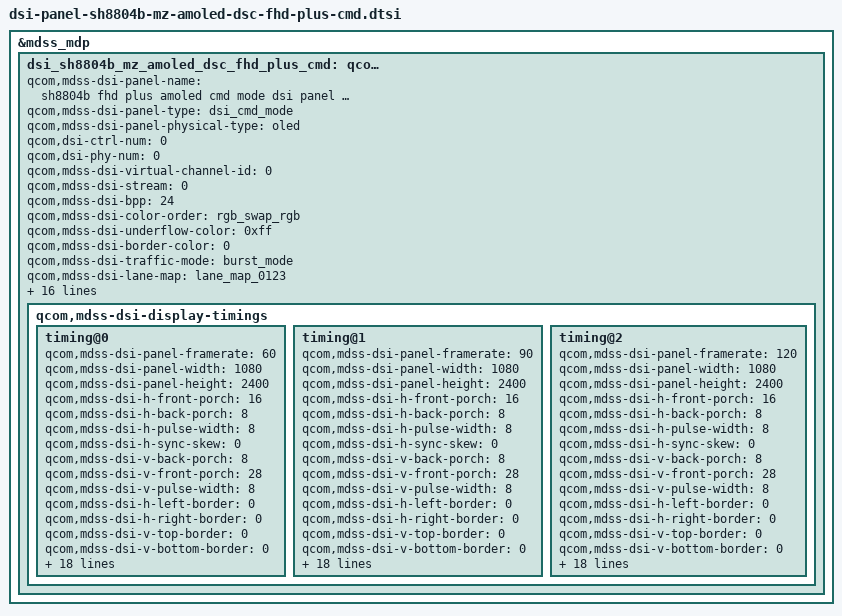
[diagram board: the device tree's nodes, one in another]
&mdss_mdp {
	dsi_sh8804b_mz_amoled_dsc_fhd_plus_cmd: qcom,mdss_dsi_sh8804b_mz_amoled_dsc_fhd_plus_cmd {
		qcom,mdss-dsi-panel-name = "sh8804b fhd plus amoled cmd mode dsi panel with DSC";
		qcom,mdss-dsi-panel-type = "dsi_cmd_mode";
		qcom,mdss-dsi-panel-physical-type = "oled";

		qcom,dsi-ctrl-num = <0>;
		qcom,dsi-phy-num = <0>;

		qcom,mdss-dsi-virtual-channel-id = <0>;
		qcom,mdss-dsi-stream = <0>;
		qcom,mdss-dsi-bpp = <24>;
		qcom,mdss-dsi-color-order = "rgb_swap_rgb";
		qcom,mdss-dsi-underflow-color = <0xff>;
		qcom,mdss-dsi-border-color = <0>;
		qcom,mdss-dsi-traffic-mode = "burst_mode";
		qcom,mdss-dsi-lane-map = "lane_map_0123";
		qcom,mdss-dsi-bllp-eof-power-mode;
		qcom,mdss-dsi-bllp-power-mode;
		qcom,mdss-dsi-lane-0-state;
		qcom,mdss-dsi-lane-1-state;
		qcom,mdss-dsi-lane-2-state;
		qcom,mdss-dsi-lane-3-state;
		qcom,mdss-dsi-dma-trigger = "trigger_sw";
		qcom,mdss-dsi-mdp-trigger = "none";
		qcom,mdss-dsi-reset-sequence = <1 20>, <0 10>, <1 20>;
		qcom,mdss-pan-physical-width-dimension = <69>;
		qcom,mdss-pan-physical-height-dimension = <154>;
		qcom,mdss-dsi-tx-eot-append;

		qcom,mdss-dsi-te-pin-select = <1>;
		qcom,mdss-dsi-te-dcs-command = <1>;
		qcom,mdss-dsi-te-check-enable;
		qcom,mdss-dsi-te-using-te-pin;

		qcom,mdss-dsi-display-timings {
			timing@0 {
				qcom,mdss-dsi-panel-framerate = <60>;
				qcom,mdss-dsi-panel-width = <1080>;
				qcom,mdss-dsi-panel-height = <2400>;
				qcom,mdss-dsi-h-front-porch = <16>;
				qcom,mdss-dsi-h-back-porch = <8>;
				qcom,mdss-dsi-h-pulse-width = <8>;
				qcom,mdss-dsi-h-sync-skew = <0>;
				qcom,mdss-dsi-v-back-porch = <8>;
				qcom,mdss-dsi-v-front-porch = <28>;
				qcom,mdss-dsi-v-pulse-width = <8>;
				qcom,mdss-dsi-h-left-border = <0>;
				qcom,mdss-dsi-h-right-border = <0>;
				qcom,mdss-dsi-v-top-border = <0>;
				qcom,mdss-dsi-v-bottom-border = <0>;
				//qcom,mdss-dsi-panel-jitter = <0x4 0x1>;
				qcom,mdss-dsi-timing-switch-command = [39 01 00 00 05 00 02 70 00];
				qcom,mdss-dsi-timing-switch-command-state = "dsi_lp_mode";
				qcom,mdss-dsi-on-command = [
					39 01 00 00 00 00 03 F0 3C 3C
					39 01 00 00 00 00 03 F1 3C 3C
					39 01 00 00 00 00 03 FF 3C 00
					39 01 00 00 00 00 05 D0 00 00 00 00
					39 01 00 00 00 00 04 B4 00 00 00
					39 01 00 00 00 00 09 B5 00 40 0A 00 00 C0 0A 00
					39 01 00 00 00 00 03 B7 21 76
					39 01 00 00 00 00 10 C1 02 0C 10 10 44 20 00 00 00 00 00 08 00 00 85
					39 01 00 00 00 00 03 FF 3C 01
					39 01 00 00 00 00 06 B0 50 10 10 15 00
					39 01 00 00 00 00 3B B1 C4 60 09 38 04 D0 02 00 00 00 01 03 00 10 09 60 00 12 00 12 00 10 03 0C 00 12 00 12 00 10 00 10 00 10 00 10 00 10 09 60 00 12 00 12 00 10 00 00 37 04 00 00 5F 09 00 00 FF 00
					39 01 00 00 00 00 17 B2 14 14 03 04 03 04 03 04 07 13 14 14 03 04 03 04 03 04 13 14 14 03
					39 01 00 00 00 00 1B B3 40 01 38 A5 C9 00 30 01 C0 A6 41 00 01 00 00 00 00 11 20 44 35 77 86 AA 9B FF
					39 01 00 00 00 00 06 B4 32 22 26 56 12
					39 01 00 00 00 00 13 B5 00 00 00 00 00 00 04 F0 20 00 00 00 00 00 00 00 00 00
					39 01 00 00 00 00 31 B7 00 FB FC 00 00 00 00 00 00 00 00 00 00 00 00 00 00 00 00 00 00 00 00 00 00 00 00 00 00 00 00 00 00 00 00 00 00 00 00 00 00 00 00 00 00 00 00 00
					39 01 00 00 00 00 0A B8 09 AA 55 AA 55 AA 55 AA 55
					39 01 00 00 00 00 29 BA 24 00 27 00 26 00 0C 00 0B 00 01 00 37 37 37 37 24 00 27 00 26 00 0C 00 0B 00 01 00 37 37 37 37 00 00 00 00 00 00 00 00
					39 01 00 00 00 00 19 BB 00 02 00 00 00 2B 00 00 00 00 79 79 00 00 79 79 00 00 79 79 00 00 79 79
					39 01 00 00 00 00 1B BC 83 01 00 07 00 09 00 0A 00 0C 00 0D 00 0F 00 E6 00 00 E6 00 00 E6 00 00 E6 00
					39 01 00 00 00 00 13 BE 03 00 00 0E 04 00 12 12 00 12 12 00 12 12 00 12 12 00
					39 01 00 00 00 00 12 C0 11 01 00 10 10 64 14 10 64 14 10 64 14 10 64 14 FF
					39 01 00 00 00 00 12 C5 21 02 00 31 00 12 AA 00 12 AA 00 12 AA 00 12 AA FF
					39 01 00 00 00 00 11 C7 66 00 66 00 66 00 00 00 00 66 00 11 00 00 00 00
					39 01 00 00 00 00 32 C8 00 00 00 00 00 00 00 00 06 06 06 00 60 10 00 00 00 00 06 20 00 00 00 00 00 00 00 00 00 00 00 00 00 00 00 00 00 00 00 00 00 00 00 00 00 00 00 00 FF
					39 01 00 00 00 00 63 C9 00 00 25 21 36 00 00 00 56 11 00 00 00 00 00 00 00 00 00 00 00 00 00 00 25 31 26 00 00 00 56 11 00 00 00 00 00 00 00 00 00 00 00 00 00 00 35 12 36 56 12 00 00 00 00 00 00 00 00 00 00 00 00 00 00 00 00 00 00 00 00 35 22 26 00 00 00 56 12 00 00 00 00 00 00 00 00 00 00 00 00 00 00 35 21 26 56 11
					39 01 00 00 00 00 17 CE 01 30 03 03 03 03 03 03 03 03 00 00 02 02 02 00 00 00 00 00 00 FF
					39 01 00 00 00 00 03 FF 3C 02
					39 01 00 00 00 00 1F B0 19 88 08 70 00 54 1E 1E 19 1E 41 10 1E 00 38 77 6C 6C 33 33 33 33 73 33 33 33 32 04 F0 33
					39 01 00 00 00 00 1F B1 09 88 08 6E 00 54 1E 1E 19 1E 41 10 1E 00 38 77 6C 6C 33 33 33 33 73 33 33 33 32 04 F0 33
					39 01 00 00 00 00 2C B2 00 00 77 19 21 29 01 03 05 07 07 08 09 0A 0D 0F 21 25 25 1C 00 77 19 21 29 01 03 05 07 08 09 0A 0B 0D 0F 25 21 21 00 00 00 00 FF
					39 01 00 00 00 00 29 B3 00 00 00 00 01 01 02 03 03 07 04 04 05 06 07 07 08 08 09 09 09 09 09 8B 8C 09 0A 09 0B 0C 0C 0C 00 0E 18 1C 00 00 21 00
					39 01 00 00 00 00 29 B3 00 00 00 00 01 01 02 03 03 07 04 04 05 06 07 07 08 08 09 09 09 09 09 8B 8C 09 0A 09 0B 0C 0C 0C 00 0E 14 18 00 00 21 00
					39 01 00 00 00 00 17 B4 BB BB B0 AA 9A 88 88 78 77 77 77 77 77 77 77 88 08 EC 44 00 21 00
					39 01 00 00 00 00 17 B5 22 22 20 11 11 11 11 00 00 00 00 00 00 00 00 00 00 02 00 00 00 FF
					39 01 00 00 00 00 20 BA 0F 0F 0F 0F 0F 0F 0F 0F 0F 0F 0F 0F 14 15 16 17 18 19 19 19 19 19 19 19 0F 0F 0F 19 19 19 00
					39 01 00 00 00 00 03 FF 3C 03
					39 01 00 00 00 00 A7 B0 00 00 FF 05 00 00 00 00 00 00 98 03 E8 03 1D 04 9A 03 E8 03 1F 04 9F 03 E9 03 24 04 A4 03 EA 03 29 04 A9 03 EB 03 2E 04 AE 03 EC 03 33 04 B3 03 ED 03 38 04 B8 03 EE 03 3D 04 BD 03 EF 03 42 04 C2 03 F0 03 47 04 C7 03 F1 03 4C 04 D2 03 F4 03 56 04 DD 03 F7 03 60 04 E8 03 FA 03 6A 04 FF 03 00 04 7F 04 16 04 06 04 94 04 2D 04 0C 04 A9 04 44 04 12 04 BE 04 44 04 12 04 BE 04 56 04 18 04 CB 04 5F 04 18 04 D2 04 5F 04 18 04 D2 04 91 04 3E 04 08 05 91 04 3E 04 08 05 91 04 3E 04 08 05 91 04 3E 04 08 05
					39 01 00 00 00 00 A7 B1 00 00 FF 05 00 00 00 00 00 00 44 03 36 03 B4 03 0C 04 FE 03 7C 04 70 04 62 04 E0 04 95 04 80 04 18 05 AB 04 94 04 3A 05 C7 04 9F 04 52 05 06 05 D0 04 90 05 10 05 D0 04 98 05 21 05 DB 04 AC 05 37 05 EB 04 C7 05 4B 05 FA 04 DB 05 69 05 0E 05 FB 05 8E 05 2A 05 21 06 AB 05 43 05 42 06 DD 05 6D 05 79 06 11 06 9B 05 B2 06 41 06 C7 05 E6 06 6B 06 EB 05 16 07 98 06 15 06 47 07 BC 06 37 06 71 07 E0 06 58 06 99 07 0C 07 82 06 CE 07 25 07 9B 06 E7 07 3F 07 B2 06 04 08 5C 07 CC 06 27 08 7C 07 EC 06 49 08
					39 01 00 00 00 00 A7 B2 00 00 FF 05 00 00 00 00 00 00 9B 03 84 01 00 00 78 04 67 04 0B 05 78 04 67 04 0B 05 B5 04 88 04 3A 05 D4 04 A2 04 5B 05 F1 04 B6 04 7D 05 39 05 EF 04 C3 05 44 05 F4 04 D2 05 5F 05 07 05 F0 05 7A 05 1C 05 0C 06 92 05 30 05 26 06 B4 05 4A 05 4B 06 DE 05 6E 05 78 06 04 06 8F 05 A2 06 3F 06 C5 05 E4 06 79 06 F9 05 26 07 AF 06 2A 06 63 07 E3 06 5C 06 9D 07 10 07 86 06 D1 07 39 07 AC 06 02 08 60 07 D2 06 2E 08 84 07 F3 06 58 08 AA 07 17 07 83 08 CC 07 36 07 AA 08 EB 07 53 07 CE 08 11 08 70 07 F4 08
					39 01 00 00 00 00 A7 B3 00 00 FF 05 00 00 00 00 00 00 89 03 C5 03 7A 01 EF 03 5F 04 55 02 83 04 6E 04 14 05 D2 04 93 04 54 05 F1 04 B1 04 7F 05 1B 05 D0 04 AB 05 67 05 11 05 F6 05 79 05 1D 05 0B 06 98 05 33 05 2C 06 B2 05 4C 05 48 06 CE 05 62 05 67 06 F7 05 85 05 95 06 24 06 AE 05 C6 06 4D 06 D3 05 F4 06 90 06 0F 06 41 07 D2 06 4C 06 8A 07 0E 07 85 06 CD 07 42 07 B6 06 0B 08 76 07 E5 06 47 08 A4 07 13 07 7C 08 CE 07 38 07 AD 08 F6 07 5E 07 DB 08 20 08 85 07 0C 09 46 08 A8 07 37 09 6A 08 CA 07 62 09 90 08 EA 07 90 09
					39 01 00 00 00 00 A7 B4 00 00 FF 05 00 00 00 00 00 00 E6 03 F1 03 8B 04 4A 04 55 04 EF 04 9C 04 71 04 21 05 E1 04 A6 04 6C 05 17 05 C9 04 A5 05 46 05 ED 04 D6 05 97 05 38 05 2A 06 AC 05 44 05 41 06 D2 05 65 05 6A 06 EE 05 7F 05 89 06 0C 06 99 05 AA 06 3A 06 C2 05 DF 06 6B 06 EF 05 16 07 99 06 19 06 4A 07 E4 06 5E 06 9E 07 29 07 9F 06 EE 07 68 07 DB 06 37 08 9F 07 0D 07 78 08 DD 07 49 07 BD 08 0C 08 73 07 F5 08 3B 08 9E 07 2D 09 6A 08 C7 07 64 09 99 08 F4 07 9B 09 C3 08 1A 08 CD 09 ED 08 3F 08 FF 09 19 09 65 08 32 0A
					39 01 00 00 00 00 A7 B5 00 00 FF 05 00 00 00 00 00 00 F6 03 ED 03 8C 04 5A 04 51 04 F0 04 9E 04 73 04 2B 05 F2 04 B2 04 82 05 2E 05 DA 04 BE 05 61 05 02 05 F2 05 B3 05 4D 05 48 06 C9 05 5E 05 61 06 ED 05 7F 05 88 06 0F 06 9C 05 AE 06 2F 06 B9 05 D0 06 60 06 E6 05 0A 07 95 06 16 06 44 07 C4 06 41 06 7B 07 0E 07 85 06 D2 07 5D 07 D0 06 28 08 9D 07 0D 07 74 08 D8 07 43 07 BA 08 15 08 7C 07 00 09 4B 08 AD 07 40 09 7F 08 DB 07 7D 09 AF 08 09 08 B6 09 E2 08 36 08 F1 09 11 09 5F 08 29 0A 3F 09 87 08 5F 0A 70 09 B2 08 99 0A
					39 01 00 00 00 00 A7 B6 00 00 FF 05 00 00 00 00 00 00 01 00 B8 03 F2 04 5E 04 50 04 F2 04 A6 04 77 04 31 05 FF 04 B8 04 8C 05 3C 05 E3 04 CD 05 71 05 0D 05 03 06 C4 05 5D 05 5B 06 DC 05 71 05 75 06 FF 05 8F 05 9C 06 23 06 AF 05 C3 06 43 06 CC 05 E7 06 76 06 FA 05 22 07 AC 06 2B 06 5F 07 E4 06 5F 06 9D 07 2B 07 A1 06 F1 07 77 07 E8 06 49 08 BA 07 27 07 96 08 F8 07 61 07 DF 08 38 08 9C 07 28 09 70 08 CE 07 6B 09 A5 08 FE 07 A9 09 D8 08 2C 08 E6 09 0E 09 5D 08 25 0A 3F 09 88 08 5F 0A 6F 09 B2 08 98 0A A2 09 DD 08 D4 0A
					39 01 00 00 00 00 A7 B7 00 00 FF 05 00 00 00 00 00 00 33 00 C1 03 EE 04 62 04 54 04 F6 04 B3 04 7E 04 3E 05 10 05 C2 04 9E 05 4F 05 F2 04 E1 05 85 05 1F 05 19 06 DA 05 70 05 73 06 F3 05 84 05 8F 06 1C 06 AA 05 BB 06 40 06 C9 05 E2 06 5F 06 E5 05 06 07 93 06 14 06 43 07 CB 06 48 06 82 07 05 07 7C 06 C2 07 4C 07 BF 06 18 08 A1 07 12 07 77 08 E1 07 4B 07 C3 08 24 08 8A 07 11 09 64 08 C4 07 5D 09 9E 08 F9 07 A1 09 D7 08 2B 08 E5 09 0D 09 5C 08 26 0A 46 09 8E 08 67 0A 7B 09 BC 08 A5 0A AE 09 E7 08 E3 0A E6 09 16 09 23 0B
					39 01 00 00 00 00 A7 B8 00 00 FF 05 00 00 00 00 00 00 44 04 43 04 9C 04 69 04 57 04 FB 04 C0 04 87 04 4B 05 22 05 CF 04 B2 05 63 05 03 05 F4 05 9D 05 33 05 33 06 F3 05 87 05 8E 06 11 06 A0 05 AF 06 38 06 C4 05 DB 06 5E 06 E5 05 04 07 7E 06 01 06 2A 07 B5 06 34 06 69 07 F1 06 6C 06 AB 07 1F 07 97 06 E3 07 76 07 E7 06 48 08 C6 07 32 07 A4 08 11 08 78 07 F9 08 54 08 B4 07 49 09 98 08 F4 07 9A 09 D6 08 2B 08 E3 09 12 09 5F 08 2A 0A 4C 09 93 08 6D 0A 8A 09 C8 08 B5 0A C2 09 F8 08 F9 0A FA 09 27 09 3B 0B 37 0A 5B 09 80 0B
					39 01 00 00 00 00 A7 B9 00 00 FF 05 00 00 00 00 00 00 42 04 38 04 01 05 80 04 57 04 01 05 D8 04 8F 04 5C 05 3B 05 E0 04 CA 05 7E 05 18 05 11 06 BB 05 4E 05 53 06 12 06 A3 05 AF 06 32 06 BC 05 D2 06 5B 06 E1 05 00 07 7F 06 04 06 2B 07 A2 06 24 06 53 07 E0 06 5D 06 98 07 1A 07 91 06 DB 07 4B 07 C1 06 16 08 A7 07 15 07 80 08 FA 07 63 07 E0 08 48 08 AB 07 3B 09 90 08 EC 07 91 09 DA 08 2F 08 E7 09 1C 09 6A 08 35 0A 5E 09 A1 08 83 0A 9D 09 D9 08 CD 0A E1 09 13 09 1C 0B 1F 0A 47 09 66 0B 5E 0A 7D 09 AC 0B A1 0A B5 09 FA 0B
					39 01 00 00 00 00 A7 BA 00 00 FF 05 00 00 00 00 00 00 41 04 2E 04 0E 05 7B 04 64 04 0E 05 FA 04 A7 04 7E 05 62 05 01 05 F4 05 AD 05 42 05 44 06 EE 05 7B 05 8C 06 4A 06 D5 05 EE 06 6C 06 F2 05 15 07 98 06 1A 06 46 07 C1 06 3F 06 74 07 E6 06 63 06 9E 07 26 07 9E 06 E8 07 65 07 DA 06 31 08 9D 07 0D 07 73 08 FE 07 65 07 E5 08 59 08 BA 07 4F 09 B0 08 08 08 B4 09 00 09 4F 08 14 0A 54 09 9B 08 76 0A A1 09 DB 08 D4 0A EE 09 1D 09 2D 0B 3A 0A 5D 09 85 0B 88 0A A0 09 DC 0B D6 0A E0 09 3E 0C 23 0B 20 0A 92 0C 74 0B 66 0A F5 0C
					39 01 00 00 00 00 A7 BB 00 00 FF 05 00 00 00 00 00 00 50 04 45 04 DD 04 86 04 68 04 17 05 1C 05 B7 04 B0 05 80 05 1B 05 14 06 D1 05 62 05 6C 06 13 06 9E 05 B3 06 72 06 FA 05 19 07 95 06 18 06 43 07 C3 06 43 06 76 07 EF 06 6A 06 A8 07 17 07 91 06 D4 07 58 07 CC 06 23 08 99 07 0A 07 6D 08 D7 07 43 07 B4 08 3D 08 A0 07 2D 09 A1 08 FB 07 A3 09 FB 08 4B 08 0D 0A 57 09 9C 08 79 0A B2 09 E9 08 E6 0A 08 0A 33 09 4B 0B 5F 0A 7B 09 AE 0B B5 0A C4 09 12 0C 10 0B 11 0A 7D 0C 69 0B 5B 0A E6 0C C4 0B A8 0A 54 0D 2B 0C FE 0A D7 0D
					39 01 00 00 00 00 A7 C0 00 00 FF 05 00 00 00 00 00 00 F2 03 03 04 8D 04 F3 03 03 04 8D 04 F5 03 04 04 8E 04 F7 03 05 04 8F 04 F9 03 06 04 90 04 FB 03 07 04 91 04 FD 03 08 04 92 04 FF 03 09 04 93 04 01 04 0A 04 94 04 03 04 0B 04 95 04 05 04 0C 04 96 04 0A 04 0E 04 99 04 0F 04 10 04 9C 04 14 04 12 04 9F 04 1E 04 16 04 A6 04 28 04 1A 04 AD 04 32 04 1E 04 B4 04 3C 04 22 04 BB 04 46 04 26 04 C2 04 50 04 2A 04 C9 04 5A 04 2A 04 D2 04 69 04 2C 04 DF 04 69 04 2C 04 DF 04 87 04 3C 04 FB 04 87 04 3C 04 FB 04 87 04 3C 04 FB 04
					39 01 00 00 00 00 A7 C1 00 00 FF 05 00 00 00 00 00 00 42 03 01 00 25 01 42 03 01 00 25 01 42 03 01 00 5C 05 CF 04 BE 04 5C 05 CF 04 BE 04 5C 05 E4 04 C9 04 72 05 10 05 F2 04 9D 05 20 05 F2 04 AC 05 33 05 FC 04 BF 05 45 05 07 05 D5 05 56 05 12 05 E7 05 72 05 21 05 03 06 92 05 3A 05 26 06 B3 05 53 05 4A 06 E3 05 78 05 7E 06 13 06 A2 05 B3 06 41 06 CA 05 E6 06 6B 06 EF 05 16 07 97 06 18 06 46 07 BC 06 39 06 70 07 DF 06 59 06 97 07 0A 07 82 06 CC 07 23 07 9B 06 E5 07 3E 07 B4 06 05 08 5C 07 CD 06 23 08 79 07 EA 06 47 08
					39 01 00 00 00 00 A7 C2 00 00 FF 05 00 00 00 00 00 00 45 04 35 04 C4 04 A2 04 93 04 2F 05 A2 04 93 04 2F 05 D3 04 B2 04 64 05 E9 04 C7 04 75 05 05 05 D6 04 94 05 4A 05 0D 05 D7 05 52 05 0E 05 DF 05 69 05 1D 05 FC 05 82 05 30 05 14 06 99 05 40 05 2E 06 BA 05 58 05 52 06 E4 05 7A 05 7F 06 06 06 98 05 A5 06 3F 06 C9 05 E5 06 79 06 FC 05 27 07 AE 06 2B 06 62 07 E3 06 5D 06 9C 07 0F 07 87 06 D1 07 39 07 AD 06 01 08 60 07 D3 06 2D 08 89 07 F9 06 5B 08 A9 07 18 07 83 08 CA 07 35 07 A8 08 E9 07 52 07 CD 08 10 08 77 07 F6 08
					39 01 00 00 00 00 A7 C3 00 00 FF 05 00 00 00 00 00 00 00 00 2E 04 D7 04 00 00 99 04 D7 04 AA 04 99 04 39 05 DF 04 BC 04 6C 05 06 05 D3 04 94 05 29 05 E8 04 B9 05 73 05 28 05 03 06 80 05 2E 05 12 06 9E 05 42 05 33 06 B9 05 58 05 51 06 D5 05 6F 05 6E 06 FA 05 8E 05 97 06 26 06 B4 05 C8 06 4F 06 D8 05 F6 06 90 06 10 06 40 07 D1 06 4D 06 8B 07 0D 07 84 06 CB 07 3F 07 B3 06 08 08 78 07 E9 06 47 08 A6 07 14 07 7C 08 CC 07 37 07 AA 08 F4 07 5B 07 D9 08 1E 08 82 07 09 09 43 08 A5 07 35 09 67 08 C5 07 60 09 8F 08 EB 07 8F 09
					39 01 00 00 00 00 A7 C5 00 00 FF 05 00 00 00 00 00 00 9A 04 00 00 0E 05 B8 04 00 00 43 05 B8 04 99 04 43 05 FF 04 C7 04 86 05 25 05 E5 04 B5 05 52 05 04 05 E4 05 9E 05 49 05 32 06 B1 05 53 05 47 06 D1 05 6D 05 6A 06 F0 05 87 05 8C 06 0E 06 A0 05 AC 06 3B 06 C6 05 DF 06 6C 06 F4 05 15 07 99 06 1B 06 49 07 E0 06 5C 06 9A 07 26 07 9E 06 EB 07 66 07 D9 06 33 08 9D 07 0C 07 75 08 DB 07 48 07 BA 08 0A 08 71 07 F2 08 39 08 9C 07 29 09 67 08 C5 07 5F 09 96 08 F1 07 96 09 C1 08 18 08 C9 09 EA 08 3D 08 FA 09 16 09 64 08 30 0A
					39 01 00 00 00 00 A7 C6 00 00 FF 05 00 00 00 00 00 00 A4 04 12 00 0B 05 BD 04 2B 00 24 05 C8 04 99 04 4B 05 05 05 CE 04 94 05 38 05 F0 04 C9 05 67 05 13 05 F9 05 B7 05 5B 05 4E 06 D3 05 6E 05 6C 06 F0 05 87 05 8C 06 14 06 A8 05 B3 06 30 06 BE 05 D2 06 60 06 E9 05 09 07 94 06 18 06 43 07 C4 06 43 06 7A 07 11 07 8A 06 D1 07 5B 07 D0 06 26 08 9B 07 0C 07 71 08 D6 07 43 07 B7 08 16 08 7F 07 FF 08 4C 08 AF 07 3C 09 7C 08 DA 07 78 09 AD 08 05 08 B3 09 E0 08 35 08 EE 09 0F 09 5E 08 25 0A 3B 09 85 08 57 0A 6E 09 AF 08 95 0A
					39 01 00 00 00 00 A7 C7 00 00 FF 05 00 00 00 00 00 00 34 04 15 04 CC 04 98 04 79 04 30 05 C2 04 9E 04 4F 05 0F 05 D6 04 9F 05 48 05 FC 04 DA 05 77 05 1F 05 0A 06 C9 05 69 05 5F 06 E0 05 7A 05 7A 06 04 06 99 05 A2 06 27 06 B7 05 C8 06 47 06 D4 05 EB 06 78 06 FE 05 23 07 AC 06 2D 06 5F 07 E4 06 60 06 9D 07 2C 07 A2 06 F2 07 76 07 E8 06 47 08 B8 07 26 07 94 08 F6 07 61 07 DD 08 37 08 9B 07 27 09 6D 08 CD 07 68 09 A2 08 FC 07 A6 09 D6 08 2B 08 E2 09 0B 09 5A 08 21 0A 3D 09 86 08 5C 0A 6D 09 B0 08 94 0A A0 09 DB 08 D4 0A
					39 01 00 00 00 00 A7 C8 00 00 FF 05 00 00 00 00 00 00 46 04 5A 04 1F 05 9E 04 7A 04 34 05 CC 04 A3 04 57 05 1C 05 DE 04 AD 05 57 05 07 05 E7 05 8A 05 2E 05 1F 06 DF 05 7C 05 77 06 F5 05 8C 05 91 06 1A 06 AC 05 BA 06 3D 06 CB 05 E1 06 5F 06 E8 05 06 07 96 06 1A 06 45 07 C8 06 47 06 7F 07 01 07 7A 06 BF 07 49 07 BD 06 15 08 9A 07 0B 07 71 08 E0 07 4B 07 C1 08 20 08 86 07 0D 09 62 08 C3 07 5B 09 9C 08 F8 07 9F 09 D2 08 27 08 DE 09 0A 09 59 08 22 0A 44 09 8C 08 64 0A 78 09 B9 08 A1 0A AC 09 E6 08 DE 0A E2 09 13 09 1F 0B
					39 01 00 00 00 00 A7 C9 00 00 FF 05 00 00 00 00 00 00 94 04 24 04 C1 04 94 04 86 04 24 05 D6 04 AA 04 63 05 2D 05 E8 04 BE 05 6C 05 16 05 FE 05 A1 05 3F 05 38 06 F6 05 8F 05 90 06 10 06 A4 05 AF 06 37 06 C7 05 DA 06 5E 06 E8 05 04 07 7E 06 04 06 29 07 B4 06 35 06 67 07 ED 06 69 06 A8 07 1E 07 98 06 E1 07 74 07 E6 06 45 08 C4 07 31 07 A2 08 0D 08 75 07 F6 08 51 08 B2 07 46 09 95 08 F1 07 96 09 D3 08 29 08 E0 09 0F 09 5C 08 27 0A 49 09 90 08 6A 0A 86 09 C5 08 B1 0A BF 09 F7 08 F5 0A F7 09 24 09 37 0B 30 0A 57 09 7A 0B
					39 01 00 00 00 00 A7 CA 00 00 FF 05 00 00 00 00 00 00 4A 04 3B 04 2A 05 97 04 89 04 2A 05 E4 04 B2 04 72 05 43 05 F8 04 D5 05 85 05 29 05 1A 06 BC 05 56 05 56 06 13 06 AA 05 B0 06 33 06 C1 05 D5 06 59 06 E3 05 FF 06 80 06 07 06 2C 07 A2 06 26 06 52 07 DD 06 5C 06 95 07 17 07 90 06 D8 07 4C 07 C3 06 16 08 A5 07 16 07 7C 08 F7 07 61 07 DD 08 45 08 A8 07 37 09 8D 08 E9 07 8D 09 D7 08 2C 08 E4 09 19 09 66 08 31 0A 5A 09 9F 08 7E 0A 9A 09 D6 08 C9 0A DE 09 10 09 18 0B 1C 0A 44 09 63 0B 5A 0A 79 09 AB 0B 9D 0A B2 09 F8 0B
					39 01 00 00 00 00 A7 CB 00 00 FF 05 00 00 00 00 00 00 7B 04 6F 04 24 05 A2 04 8F 04 32 05 07 05 C3 04 8F 05 6A 05 14 05 FB 05 B4 05 50 05 4D 06 F0 05 83 05 8E 06 4D 06 DB 05 EF 06 6D 06 F6 05 14 07 98 06 1D 06 45 07 C1 06 42 06 75 07 E7 06 64 06 9F 07 24 07 9D 06 E7 07 63 07 D8 06 2F 08 9B 07 0B 07 71 08 FC 07 63 07 E2 08 57 08 B8 07 4D 09 AD 08 06 08 B2 09 FC 08 4C 08 11 0A 51 09 97 08 73 0A 9F 09 DA 08 CE 0A EB 09 1A 09 2A 0B 37 0A 5A 09 82 0B 86 0A 9E 09 DE 0B D3 0A DD 09 37 0C 20 0B 1D 0A 8F 0C 71 0B 61 0A F8 0C
					39 01 00 00 00 00 A7 CC 00 00 FF 05 00 00 00 00 00 00 B2 04 6F 02 1E 00 B3 04 93 04 22 05 0E 05 D2 04 A5 05 87 05 2A 05 1B 06 D4 05 6C 05 6F 06 14 06 A3 05 B7 06 73 06 FD 05 1A 07 96 06 1C 06 43 07 C3 06 44 06 77 07 EE 06 6D 06 A7 07 17 07 92 06 D5 07 57 07 CD 06 23 08 98 07 0A 07 6D 08 D5 07 41 07 B4 08 3A 08 9D 07 2A 09 9D 08 F8 07 A0 09 F8 08 49 08 0A 0A 53 09 97 08 75 0A AF 09 E8 08 E1 0A 05 0A 30 09 48 0B 5A 0A 78 09 AB 0B B1 0A C0 09 0D 0C 0C 0B 0D 0A 78 0C 65 0B 57 0A E3 0C BF 0B A4 0A 52 0D 29 0C FC 0A D2 0D
					39 01 00 00 00 00 A7 D0 00 00 FF 05 00 00 00 00 00 00 35 04 57 04 9E 04 35 04 57 04 9F 04 36 04 57 04 A1 04 37 04 57 04 A3 04 38 04 57 04 A5 04 39 04 57 04 A7 04 3A 04 57 04 A9 04 3B 04 57 04 AB 04 3C 04 57 04 AD 04 3D 04 57 04 AF 04 3E 04 57 04 B1 04 41 04 57 04 B5 04 44 04 57 04 B9 04 47 04 57 04 BD 04 4E 04 57 04 C5 04 55 04 57 04 CD 04 5C 04 57 04 D5 04 63 04 57 04 DD 04 6A 04 57 04 E5 04 71 04 57 04 ED 04 79 04 57 04 EF 04 85 04 58 04 FB 04 85 04 58 04 FB 04 8F 04 58 04 06 05 91 04 58 04 07 05 9A 04 59 04 0A 05
					39 01 00 00 00 00 A7 D1 00 00 FF 05 00 00 00 00 00 00 A8 04 B0 04 34 05 AF 04 B4 04 3B 05 BE 04 BC 04 4A 05 CD 04 C4 04 59 05 DC 04 CC 04 68 05 EB 04 D4 04 77 05 FC 04 DD 04 89 05 0A 05 E4 04 97 05 1A 05 EC 04 A9 05 2F 05 F8 04 BE 05 3D 05 00 05 CD 05 60 05 17 05 F2 05 7F 05 2E 05 13 06 9D 05 44 05 33 06 D7 05 70 05 73 06 06 06 99 05 A7 06 33 06 BF 05 D9 06 5C 06 E2 05 08 07 84 06 06 06 34 07 A8 06 27 06 5D 07 CB 06 46 06 85 07 EC 06 65 06 AB 07 0A 07 7F 06 CC 07 27 07 9B 06 EE 07 42 07 B5 06 0D 08 58 07 CE 06 2F 08
					39 01 00 00 00 00 A7 D2 00 00 FF 05 00 00 00 00 00 00 9A 04 98 04 2C 05 A7 04 A2 04 38 05 C2 04 B6 04 50 05 DD 04 CA 04 68 05 F1 04 D5 04 7E 05 07 05 DF 04 96 05 21 05 F0 04 B1 05 37 05 FA 04 C6 05 4F 05 09 05 E2 05 64 05 18 05 F7 05 7C 05 29 05 10 06 A6 05 4A 05 3D 06 CC 05 69 05 68 06 F0 05 85 05 8F 06 32 06 BD 05 D8 06 6E 06 F3 05 1B 07 9F 06 1F 06 54 07 D0 06 4C 06 8B 07 FC 06 74 06 BE 07 25 07 9B 06 ED 07 4C 07 BF 06 19 08 6F 07 E0 06 43 08 91 07 FE 06 6A 08 B3 07 1F 07 92 08 D1 07 39 07 B5 08 F1 07 57 07 DB 08
					39 01 00 00 00 00 A7 D3 00 00 FF 05 00 00 00 00 00 00 62 04 6E 04 C3 04 B3 04 A8 04 2D 05 CA 04 BA 04 58 05 ED 04 CA 04 7E 05 05 05 DE 04 98 05 27 05 EE 04 B7 05 47 05 06 05 D8 05 60 05 14 05 F4 05 7E 05 2A 05 15 06 99 05 3F 05 30 06 B2 05 52 05 4A 06 E3 05 7B 05 81 06 0F 06 A0 05 B1 06 38 06 C3 05 E0 06 81 06 04 06 32 07 C3 06 42 06 7B 07 FC 06 74 06 BD 07 31 07 A6 06 F9 07 61 07 D2 06 32 08 91 07 01 07 6A 08 B7 07 22 07 95 08 E0 07 48 07 C4 08 06 08 6B 07 F2 08 2B 08 8D 07 1D 09 4F 08 AE 07 48 09 75 08 D1 07 72 09
					39 01 00 00 00 00 A7 D4 00 00 FF 05 00 00 00 00 00 00 76 04 4F 04 E6 04 76 04 A9 04 42 05 D1 04 BD 04 5E 05 FA 04 D5 04 88 05 22 05 EB 04 B3 05 49 05 05 05 DA 05 71 05 20 05 04 06 90 05 37 05 26 06 B3 05 51 05 4D 06 D2 05 6C 05 6F 06 EE 05 82 05 8B 06 24 06 B2 05 C8 06 54 06 DD 05 FE 06 82 06 04 06 32 07 D2 06 50 06 8D 07 18 07 8F 06 DC 07 56 07 CA 06 25 08 8F 07 FF 06 67 08 C4 07 2F 07 A4 08 F8 07 62 07 E1 08 25 08 88 07 15 09 52 08 B1 07 4A 09 80 08 DA 07 7F 09 AA 08 00 08 B1 09 D3 08 25 08 E3 09 FE 08 49 08 17 0A
					39 01 00 00 00 00 A7 D5 00 00 FF 05 00 00 00 00 00 00 08 00 46 04 5D 00 6C 00 AA 04 C1 00 D3 04 BB 04 64 05 07 05 D5 04 96 05 34 05 F3 04 C7 05 5F 05 12 05 F1 05 8B 05 32 05 20 06 AD 05 4C 05 45 06 D0 05 6A 05 6D 06 F2 05 87 05 90 06 11 06 A0 05 B2 06 49 06 D3 05 F3 06 7D 06 01 06 2C 07 AD 06 2B 06 63 07 01 07 7A 06 C3 07 49 07 BE 06 18 08 89 07 FA 06 61 08 C8 07 33 07 A9 08 01 08 66 07 EB 08 3A 08 9B 07 2A 09 68 08 C4 07 63 09 99 08 F0 07 9D 09 C9 08 1C 08 D7 09 F7 08 44 08 0D 0A 25 09 6C 08 43 0A 53 09 94 08 7A 0A
					39 01 00 00 00 00 A7 D6 00 00 FF 05 00 00 00 00 00 00 49 04 40 04 D3 04 AD 04 A4 04 37 05 D9 04 BE 04 6A 05 0F 05 DC 04 9F 05 3E 05 FC 04 D0 05 6D 05 1C 05 01 06 99 05 3D 05 30 06 BD 05 5A 05 57 06 E3 05 79 05 80 06 08 06 97 05 A8 06 24 06 B2 05 C8 06 5E 06 E6 05 0B 07 93 06 16 06 46 07 C3 06 43 06 7C 07 1C 07 94 06 E3 07 65 07 D8 06 38 08 A8 07 16 07 85 08 E9 07 54 07 CE 08 23 08 87 07 14 09 59 08 B8 07 53 09 8E 08 E7 07 91 09 C1 08 15 08 CD 09 F3 08 42 08 09 0A 24 09 6C 08 42 0A 53 09 96 08 7F 0A 81 09 BF 08 B7 0A
					39 01 00 00 00 00 A7 D7 00 00 FF 05 00 00 00 00 00 00 AB 04 01 00 2F 05 E0 04 01 00 4F 05 E0 04 C2 04 71 05 1B 05 E5 04 AB 05 4F 05 07 05 E2 05 7F 05 2A 05 14 06 AE 05 4E 05 47 06 D3 05 6C 05 6F 06 FA 05 8D 05 99 06 1D 06 AB 05 C1 06 3D 06 C9 05 E6 06 7B 06 FF 05 2A 07 B1 06 30 06 68 07 EA 06 63 06 A8 07 3C 07 B1 06 09 08 8A 07 FB 06 62 08 CF 07 3A 07 B2 08 11 08 76 07 FE 08 4E 08 AD 07 47 09 88 08 E3 07 8B 09 C0 08 14 08 CD 09 F6 08 44 08 0D 0A 2B 09 73 08 4C 0A 60 09 A0 08 88 0A 94 09 CC 08 C7 0A C6 09 F6 08 07 0B
					39 01 00 00 00 00 A7 D8 00 00 FF 05 00 00 00 00 00 00 AD 04 00 00 41 05 B4 04 A8 04 41 05 EA 04 C7 04 7A 05 2A 05 F0 04 BA 05 61 05 14 05 F5 05 98 05 3D 05 2F 06 C9 05 63 05 63 06 EC 05 82 05 8B 06 15 06 A5 05 B8 06 39 06 C5 05 E0 06 5B 06 E3 05 07 07 9E 06 1F 06 51 07 D7 06 54 06 91 07 09 07 83 06 CA 07 65 07 DA 06 35 08 B4 07 22 07 93 08 FD 07 64 07 E6 08 41 08 A2 07 38 09 82 08 DC 07 84 09 C2 08 16 08 CD 09 FB 08 4A 08 13 0A 35 09 7C 08 57 0A 6E 09 AD 08 9A 0A A7 09 DE 08 DD 0A DF 09 0E 09 1E 0B 18 0A 3C 09 62 0B
					39 01 00 00 00 00 A7 D9 00 00 FF 05 00 00 00 00 00 00 D0 00 CF 00 4F 05 BB 04 AA 04 51 05 FA 04 CE 04 87 05 3D 05 F9 04 D0 05 7C 05 27 05 12 06 B3 05 52 05 4B 06 E6 05 7D 05 84 06 0C 06 9D 05 AE 06 36 06 C4 05 DE 06 60 06 E8 05 0B 07 81 06 04 06 30 07 C5 06 44 06 7D 07 01 07 7B 06 C2 07 35 07 AC 06 FE 07 96 07 06 07 6D 08 E8 07 51 07 CE 08 35 08 98 07 29 09 7E 08 DA 07 80 09 C4 08 17 08 D1 09 06 09 53 08 1E 0A 48 09 8C 08 6B 0A 88 09 C2 08 B7 0A C7 09 F8 08 01 0B 04 0A 2C 09 4B 0B 43 0A 61 09 93 0B 83 0A 96 09 D8 0B
					39 01 00 00 00 00 A7 DE 00 00 FF 05 00 00 00 00 00 00 92 04 9A 04 32 05 C0 04 B0 04 51 05 0F 05 DD 04 9F 05 61 05 15 05 F5 05 A7 05 49 05 3F 06 E3 05 7A 05 80 06 1B 06 AB 05 BF 06 46 06 D0 05 EE 06 76 06 FB 05 24 07 9F 06 20 06 53 07 C3 06 43 06 7D 07 0B 07 84 06 CE 07 4A 07 BF 06 16 08 83 07 F4 06 59 08 EA 07 53 07 D3 08 47 08 A8 07 3D 09 9D 08 F5 07 A3 09 EE 08 3F 08 02 0A 3E 09 84 08 60 0A 8C 09 C5 08 BD 0A D7 09 05 09 16 0B 22 0A 45 09 6D 0B 6E 0A 84 09 C4 0B BA 0A C5 09 1D 0C 08 0B 04 0A 77 0C 54 0B 45 0A D4 0C
					39 01 00 00 00 00 A7 DF 00 00 FF 05 00 00 00 00 00 00 26 03 A1 04 05 05 C8 04 B4 04 58 05 24 05 E9 04 B5 05 7F 05 29 05 14 06 C7 05 62 05 62 06 06 06 99 05 A7 06 41 06 CD 05 EA 06 6F 06 F5 05 1C 07 A2 06 23 06 55 07 CA 06 49 06 85 07 F4 06 6E 06 B2 07 3D 07 B3 06 0A 08 7E 07 F0 06 53 08 BB 07 29 07 9B 08 2A 08 8E 07 1B 09 8E 08 E9 07 92 09 E8 08 38 08 FB 09 44 09 89 08 66 0A 9C 09 D4 08 D1 0A F1 09 1C 09 35 0B 47 0A 65 09 98 0B 9D 0A AD 09 FA 0B F6 0A F6 09 61 0C 4D 0B 3F 0A CA 0C AA 0B 8B 0A 39 0D 0C 0C DF 0A B5 0D
					39 01 00 00 00 00 A7 BD 00 00 FF 05 00 00 00 00 00 00 F9 00 00 00 09 01 E8 03 01 00 37 04 00 04 6F 00 92 04 00 04 6F 02 92 04 0B 04 FE 03 9C 04 2B 04 11 04 BA 04 51 04 28 04 E0 04 7D 04 43 04 10 05 8C 04 4D 04 20 05 8C 04 4D 04 20 05 A4 04 62 04 39 05 D2 04 87 04 6A 05 F0 04 9A 04 8B 05 0F 05 B3 04 AD 05 41 05 E1 04 E1 05 72 05 0C 05 14 06 AA 05 36 05 58 06 D3 05 5B 05 86 06 FC 05 7F 05 B4 06 20 06 A0 05 DE 06 43 06 C0 05 06 07 64 06 DE 05 2B 07 85 06 FD 05 51 07 A2 06 1A 06 72 07 C0 06 38 06 95 07 D9 06 4E 06 B1 07
					39 01 00 00 00 00 A7 BE 00 00 FF 05 00 00 00 00 00 00 F2 01 00 00 12 02 F0 03 01 00 56 04 00 04 9E 01 92 04 0C 04 FF 03 9D 04 3A 04 1A 04 C8 04 72 04 3C 04 04 05 8C 04 4D 04 20 05 95 04 55 04 29 05 C0 04 7C 04 57 05 D5 04 88 04 6E 05 E9 04 95 04 84 05 15 05 B8 04 B4 05 39 05 D8 04 DA 05 53 05 F5 04 EF 05 A3 05 2F 05 4F 06 DB 05 62 05 8F 06 12 06 93 05 CE 06 41 06 BE 05 04 07 6E 06 E7 05 36 07 99 06 11 06 67 07 C1 06 39 06 97 07 E4 06 57 06 BE 07 08 07 79 06 E6 07 2B 07 99 06 0C 08 46 07 B3 06 28 08 58 07 BF 06 4F 08
					39 01 00 00 00 00 A7 BF 00 00 FF 05 00 00 00 00 00 00 E4 03 01 00 25 04 00 04 01 00 92 04 00 04 F8 03 92 04 3C 04 1B 04 C9 04 8C 04 4D 04 20 05 8C 04 4D 04 20 05 C7 04 82 04 5E 05 DF 04 8D 04 79 05 FE 04 A5 04 9A 05 1B 05 BD 04 BA 05 35 05 D3 04 D7 05 59 05 FB 04 F4 05 96 05 24 05 41 06 C0 05 4A 05 70 06 0B 06 8D 05 C6 06 4C 06 C8 05 10 07 89 06 01 06 55 07 C0 06 38 06 95 07 F0 06 62 06 CB 07 23 07 92 06 04 08 48 07 B5 06 2A 08 60 07 C5 06 61 08 97 07 FF 06 8D 08 BD 07 21 07 B8 08 E2 07 43 07 E3 08 04 08 62 07 09 09
					39 01 00 00 00 00 A7 BC 00 00 FF 05 00 00 00 00 00 00 7E 02 8A 02 C6 03 D6 02 CC 02 1E 04 62 03 6D 03 AB 04 08 04 F9 03 64 05 89 04 67 04 EC 05 F3 04 C6 04 5C 06 5F 05 25 05 DD 06 A9 05 64 05 23 07 F2 05 A6 05 70 07 36 06 E1 05 B4 07 76 06 1A 06 F4 07 E3 06 7A 06 5F 08 46 07 D3 06 C0 08 A1 07 24 07 19 09 43 08 B4 07 B9 09 D4 08 33 08 53 0A 59 09 AA 08 E6 0A D7 09 18 09 73 0B 51 0A 83 09 FD 0B C2 0A E4 09 83 0C 34 0B 44 0A 03 0D A4 0B A2 0A 82 0D 17 0C 01 0B 03 0E 83 0C 5E 0B 82 0E F6 0C B9 0B 01 0F 67 0D 17 0C 82 0F
					39 01 00 00 00 00 A7 E4 00 00 FF 05 84 0D D4 0B EA 0F 84 0D D4 0B EA 0F 84 0D D4 0B EA 0F 84 0D D4 0B EA 0F 84 0D D4 0B EA 0F 84 0D D4 0B EA 0F 84 0D D4 0B EA 0F 84 0D D4 0B EA 0F 84 0D D4 0B EA 0F 84 0D D4 0B EA 0F 84 0D D4 0B EA 0F 84 0D D4 0B EA 0F 84 0D D4 0B EA 0F 84 0D D4 0B EA 0F 84 0D D4 0B EA 0F 84 0D D4 0B EA 0F 84 0D D4 0B EA 0F 84 0D D4 0B EA 0F 84 0D D4 0B EA 0F 84 0D D4 0B EA 0F 84 0D D4 0B EA 0F 84 0D D4 0B EA 0F 84 0D D4 0B EA 0F 84 0D D4 0B EA 0F 84 0D D4 0B EA 0F 84 0D D4 0B EA 0F 84 0D D4 0B EA 0F
					39 01 00 00 00 00 03 FF 3C 04
					39 01 00 00 00 00 2C B2 00 0A 77 66 55 44 33 22 11 11 10 00 00 00 00 00 FF 7E FE 7E FD 7D FD 7D FC 7C FC 7C FB BB 7B 3A 1A FA DA BB 99 79 59 38 18 08 FE
					39 01 00 00 00 00 09 B3 0C 02 3C 00 00 00 00 00
					39 01 00 00 00 00 03 FF 3C 05
					39 01 00 00 00 00 17 B1 F0 01 C0 08 22 02 7C 08 DE 60 00 00 00 00 00 00 00 00 00 00 00 00
					39 01 00 00 00 00 81 D0 11 00 00 89 30 80 09 60 04 38 00 14 02 1C 02 1C 02 00 02 0E 00 20 03 2E 00 07 00 0C 03 00 03 15 18 00 10 F0 03 0C 20 00 06 0B 0B 33 0E 1C 2A 38 46 54 62 69 70 77 79 7B 7D 7E 01 02 01 00 09 40 09 BE 19 FC 19 FA 19 F8 1A 38 1A 78 1A B6 2A F6 2B 34 2B 74 3B 74 6B F4 00 00 00 00 00 00 00 00 00 00 00 00 00 00 00 00 00 00 00 00 00 00 00 00 00 00 00 00 00 00 00 00 00 00 00 00 00 00 00 00
					39 01 00 00 00 00 81 D1 11 00 00 89 30 80 09 60 04 38 00 14 02 1C 02 1C 02 00 02 0E 00 20 03 2E 00 07 00 0C 03 00 03 15 18 00 10 F0 03 0C 20 00 06 0B 0B 33 0E 1C 2A 38 46 54 62 69 70 77 79 7B 7D 7E 01 02 01 00 09 40 09 BE 19 FC 19 FA 19 F8 1A 38 1A 78 1A B6 2A F6 2B 34 2B 74 3B 74 6B F4 00 00 00 00 00 00 00 00 00 00 00 00 00 00 00 00 00 00 00 00 00 00 00 00 00 00 00 00 00 00 00 00 00 00 00 00 00 00 00 00
					39 01 00 00 00 00 03 FF 3C 0A
					39 01 00 00 00 00 15 B0 00 00 10 00 00 00 00 00 00 00 00 00 00 00 00 00 00 00 00 00
					39 01 00 00 00 00 03 FF 3C 0E
					39 01 00 00 00 00 07 B0 33 00 60 09 38 04
					39 01 00 00 00 00 11 B1 55 00 00 00 44 00 44 40 04 40 04 40 04 19 00 00
					39 01 00 00 00 00 11 B2 41 34 00 f3 37 00 44 30 3f 40 04 40 04 19 00 00
					39 01 00 00 00 00 11 B3 49 00 99 00 48 17 5f 80 04 70 91 80 04 19 00 00
					39 01 00 00 00 00 11 B4 4d 34 99 ef 37 17 5f f0 3e 70 91 80 04 19 00 00
					39 01 00 00 00 00 11 B5 03 12 00 f4 44 0f 55 c0 21 d0 02 e0 01 00 00 00
					39 01 00 00 00 00 11 B6 10 22 00 99 ab 00 12 b0 2a 20 01 20 01 00 00 00
					39 01 00 00 00 00 11 B7 4a 11 00 9d dc 12 52 c0 1d 20 01 e0 03 0a 00 00
					39 01 00 00 00 00 11 B8 42 22 00 5c 9a 12 52 c0 25 20 01 e0 03 0a 00 00
					39 01 00 00 00 00 11 B9 84 12 00 c8 1b 00 14 70 1c 50 01 60 01 01 00 00
					39 01 00 00 00 00 11 BA 88 22 00 1c 6f 00 14 f0 26 40 01 50 01 01 00 00
					39 01 00 00 00 00 39 BB 03 03 00 45 f2 00 00 01 10 10 10 00 00 00 05 00 09 00 00 45 16 01 10 10 10 00 00 00 07 44 09 37 37 45 16 01 10 10 10 00 00 00 01 03 99 49 ee 5f 5f 01 10 10 10 00 00 00
					39 01 00 00 00 00 39 BC 02 12 00 dd 5b 51 51 01 20 20 20 20 20 20 12 00 11 be d2 36 36 aa 20 20 20 20 20 20 02 00 11 be d2 40 40 ff 20 20 00 00 00 00 12 00 11 be d2 4a 4a ff 20 20 20 20 00 00
					39 01 00 00 00 00 39 BD 00 04 aa a3 0c 4f 4f 01 10 10 10 00 00 00 16 44 09 af af b5 a2 01 10 10 10 00 00 00 02 00 11 be d2 68 68 ed 10 10 20 20 10 10 06 11 00 f4 f4 be d2 ff 80 10 00 00 00 00
					39 01 00 00 00 00 39 BE 02 04 00 00 f0 00 00 01 80 00 80 00 80 00 00 04 55 00 f0 ff ff 01 80 00 80 00 80 00 04 55 05 03 03 13 ec 01 40 00 80 00 80 00 06 22 00 1c 1c be d2 eb 0c 20 80 10 0e 0d
					39 01 00 00 00 00 39 BF 16 22 00 26 26 be d2 9c 13 40 25 0f 63 21 06 22 00 30 30 be d2 ff 21 10 42 10 63 10 02 00 00 64 64 f9 f9 ff 20 20 20 20 20 20 12 00 00 6e 6e f9 f9 ff 20 20 20 20 20 20
					39 01 00 00 00 00 39 C0 12 11 00 2c 2c f7 f7 ff 40 10 40 20 40 10 02 11 00 36 36 f7 f7 ff 14 20 14 10 14 20 16 33 00 1b 1b c8 c8 ff 20 20 20 20 20 20 14 33 00 1b 1b d2 d2 ff 20 20 20 20 20 20
					39 01 00 00 00 00 41 C1 00 01 02 03 04 06 07 08 09 0a 0c 0d 0e 0f 10 12 13 14 15 16 18 19 1a 1b 1c 1e 1f 20 21 22 24 25 26 27 28 2a 2b 2c 2d 2e 30 31 32 33 34 36 37 38 39 3a 3c 3d 3e 3f 40 42 43 44 45 46 48 49 4a 4b
					39 01 00 00 00 00 41 C2 00 00 00 00 00 00 00 00 00 00 00 00 00 00 00 00 00 00 00 00 00 00 00 00 00 00 00 00 00 00 00 00 00 00 00 00 00 00 00 00 00 00 00 00 00 00 00 00 00 00 00 00 00 00 00 00 00 00 00 00 00 00 00 00
					39 01 00 00 00 00 41 C3 00 02 05 08 0b 0e 10 13 16 19 1c 1e 21 24 27 2a 2c 2f 32 35 38 3a 3d 40 43 46 48 4b 4e 51 54 56 59 5c 5f 62 64 67 6a 6d 70 72 75 78 7b 7d 80 83 86 89 8c 8e 91 94 97 9a 9c 9f a2 a5 a8 aa ad b0
					39 01 00 00 00 00 41 C4 00 03 07 0a 0e 12 15 19 1c 20 24 27 2b 2e 32 36 39 3d 40 44 48 4b 4f 52 56 5a 5d 61 64 68 6c 6f 73 76 7a 7e 81 85 88 8c 90 93 97 9a 9e a2 a5 a9 ac b0 b4 b7 bb be c2 c6 c9 cd d0 d4 d8 db df e2
					39 01 00 00 00 00 41 C5 00 04 08 0c 10 14 18 1c 20 24 28 2c 30 34 38 3c 40 44 48 4c 50 54 58 5c 60 64 68 6c 70 74 78 7c 80 84 88 8c 90 94 98 9c a0 a4 a8 ac b0 b4 b8 bc c0 c4 c8 cc d0 d4 d8 dc e0 e4 e8 ec f0 f4 f8 fc
					39 01 00 00 00 00 41 C6 00 00 00 00 00 00 01 01 02 03 04 05 06 07 09 0a 0c 0d 0f 11 13 16 18 1b 1d 20 23 26 29 2d 30 34 37 3b 3f 44 48 4d 51 56 5b 60 65 6b 70 76 7c 82 88 8e 95 9c a2 a9 b0 b8 bf c7 cf d7 df e7 ef f8
					39 01 00 00 00 00 41 C7 00 26 34 3f 48 50 57 5d 63 68 6d 72 77 7b 80 84 88 8b 8f 93 96 99 9d a0 a3 a6 a9 ac af b2 b5 b7 ba bd bf c2 c4 c7 c9 cb ce d0 d2 d5 d7 d9 db de e0 e2 e4 e6 e8 ea ec ee f0 f2 f4 f6 f8 f9 fb fd
					39 01 00 00 00 00 41 C8 00 12 1d 25 2d 33 3a 40 45 4b 50 55 59 5e 62 67 6b 6f 73 77 7b 7f 83 86 8a 8e 91 95 98 9b 9f a2 a5 a8 ac af b2 b5 b8 bb be c1 c4 c7 ca cd cf d2 d5 d8 db dd e0 e3 e5 e8 eb ed f0 f2 f5 f8 fa fd
					39 01 00 00 00 00 51 C9 00 00 00 00 00 00 50 55 55 55 55 55 55 aa aa aa 00 0a 14 1e 28 32 3c 46 50 5a 64 6e 78 82 8c 96 a0 aa b4 be c8 d2 dc e6 f0 fa 04 0e 18 22 2c 36 40 4a 54 5e 68 72 7c 86 90 9a a4 ae b8 c2 cc d6 e0 ea f4 fe 08 12 1c 26 30 3a 44 4e 58 62 6c 76
					39 01 00 00 00 00 51 CA aa aa aa fe ff ff ff ff ff ff ff ff ff ff ff ff 80 8a 94 9e a8 b2 bc c6 d0 da e4 ee f8 02 0c 16 20 2a 34 3e 48 52 5c 66 70 7a 84 8e 98 a2 ac b6 c0 ca d4 de e8 f2 fc ff ff ff ff ff ff ff ff ff ff ff ff ff ff ff ff ff ff ff ff ff ff ff ff ff
					39 01 00 00 00 00 79 CB ff 5a 01 00 00 00 00 00 00 00 00 00 00 00 00 00 00 00 00 00 00 00 00 00 ff e8 84 20 bc 58 f4 90 2c c8 64 00 00 00 00 00 00 00 00 00 00 00 00 00 00 00 00 00 00 00 00 00 00 00 00 00 00 00 00 00 00 00 00 00 00 00 00 00 00 00 00 00 00 00 00 00 00 00 00 00 00 00 00 00 00 00 00 00 00 00 00 00 00 00 00 00 00 00 00 00 00 00 00 00 00 00 00 00 00 00 00 00 00 00 00 00
					39 01 00 00 00 00 29 CC 00 00 00 00 00 00 00 00 00 02 04 06 08 0a 0c 0e 10 12 14 16 18 1a 1c 1e 20 22 24 26 28 2a 2c 2e 30 32 34 36 38 3a 3c 3e
					39 01 00 00 00 00 19 CD 00 00 00 00 00 00 00 00 00 00 00 00 00 00 00 00 00 00 00 00 00 00 00 00
					39 01 00 00 00 00 03 FF 3C 0F
					39 01 00 00 00 00 4B B0 00 01 00 72 00 F0 01 A4 02 BC 03 A2 04 38 05 14 06 40 07 FF 0C 1C 0F FF 07 FF 0F FF 03 FF 07 FF 0F FF 00 00 00 00 00 00 00 00 00 00 00 00 00 00 00 00 00 00 00 00 00 00 00 00 00 00 00 00 00 00 00 00 00 00 00 00 00 00 03 FF
					39 01 00 00 00 00 30 B1 00 00 01 00 72 00 F0 01 A4 02 BC 03 A2 04 38 05 14 06 40 0F FF 0F FF 07 FF 0F FF 03 FF 07 FF 0F FF 0F FF 0F FF 0F FF 0F FF 0F FF 00 00 00 00
					39 01 00 00 00 00 65 B2 00 00 0E 10 0E 10 0E 10 0E 10 0E 10 0E 10 0E 10 0E 10 0E 10 0E 10 0E 10 0E 10 00 00 09 C4 09 C4 09 C4 09 C4 09 C4 09 C4 09 C4 09 C4 09 C4 09 C4 09 C4 09 C4 00 00 09 C4 09 C4 09 C4 09 C4 09 C4 09 C4 09 C4 09 C4 09 C4 09 C5 09 C4 09 C4 00 00 09 C4 09 C4 09 C4 09 C4 09 C4 09 C4 09 C4 09 C4 09 C4 09 C4
					39 01 00 00 00 00 27 B3 00 00 00 00 00 00 00 00 08 08 08 08 08 08 08 08 08 08 08 08 08 08 08 08 08 08 08 08 08 08 08 08 08 08 08 08 00 C0
					39 01 00 00 00 00 14 B4 01 02 07 01 5A 50 46 99 03 33 03 CC 02 33 00 66 00 99 00
					39 01 00 00 00 00 2E B5 0B 03 04 46 00 64 00 32 00 04 04 10 80 24 24 4C 2B 00 00 35 01 4C 00 00 00 00 00 24 24 00 00 00 00 06 00 00 00 24 02 00 55 55 00 00 00
					39 01 00 00 00 00 24 B6 00 01 01 23 45 67 01 23 45 67 05 04 03 02 01 00 00 00 00 00 00 00 00 00 00 00 00 00 00 00 00 00 00 00 00
					39 01 00 00 00 00 03 FF 3C 10
					39 01 00 00 00 00 09 B0 15 60 09 38 04 0e 01 00
					39 01 00 00 00 00 4C B1 00 00 00 00 00 00 00 03 01 00 00 03 41 17 00 00 01 17 09 00 00 00 00 00 00 00 00 00 00 00 00 00 03 01 00 00 03 41 17 00 00 01 17 09 00 00 00 00 00 00 00 00 00 00 00 00 09 17 01 00 00 17 41 03 00 00 01 03 00 00 00 00 00 00 00
					39 01 00 00 00 00 4C B2 00 00 00 00 00 00 09 17 01 00 00 17 41 03 00 00 01 03 00 00 00 00 00 00 00 00 00 00 00 00 00 00 03 01 00 00 03 41 17 00 00 01 17 09 00 00 00 00 00 00 00 00 00 00 00 00 00 03 01 00 00 03 41 17 00 00 01 17 09 00 00 00 00 00 00
					39 01 00 00 00 00 4C B3 00 00 00 00 00 00 09 17 01 00 00 17 41 03 00 00 01 03 00 00 00 00 00 00 00 00 00 00 00 00 00 00 03 01 00 00 03 41 17 00 00 01 17 09 00 00 00 00 00 00 00 00 00 00 00 00 00 03 01 00 00 03 41 17 00 00 01 17 09 00 00 00 00 00 00
					39 01 00 00 00 00 4C B4 00 00 00 00 00 00 00 03 01 00 00 03 41 17 00 00 01 17 09 00 00 00 00 00 00 00 00 00 00 00 00 00 03 01 00 00 03 41 17 00 00 01 17 09 00 00 00 00 00 00 00 00 00 00 00 00 09 17 01 00 00 17 41 03 00 00 01 03 00 00 00 00 00 00 00
					39 01 00 00 00 00 03 FF 3C 11
					39 01 00 00 00 00 4F B1 FF FF FF FF FF FF FF FF FF FB FF FF F9 FF FF F3 FF FC F0 FF FA EC FF F9 E7 FF F5 DA FF EF CB FF E9 B7 FF DE 9D FF CA 6F FF FF FF FF FF FF FF FF FF FF FF FF FF FF FF FF FF FF FF FF FF FF FF FF FF FF FF FF FF FF FF FF FF FF FF FF FF 00
					39 01 00 00 00 00 03 FF 3C 0B
					39 01 00 00 00 00 05 B3 01 01 00 B0
					39 01 00 00 05 00 02 70 00
					39 01 00 00 00 00 02 03 11
					39 01 00 00 00 00 05 2A 00 00 04 37
					39 01 00 00 00 00 05 2B 00 00 09 5F
					39 01 00 00 00 00 03 44 05 FF
					39 01 00 00 00 00 02 35 00
					39 01 00 00 00 00 03 4A FF 03
					39 01 00 00 00 00 03 4C FF 03
					39 01 00 00 00 00 03 51 FF 07
					39 01 00 00 00 00 02 53 21
					39 01 00 00 00 00 02 7B 01
					05 01 00 00 0A 00 02 11 00
					05 01 00 00 19 00 02 29 00
				];
				qcom,mdss-dsi-off-command = [
					05 01 00 00 34 00 02 10 00
					05 01 00 00 14 00 02 28 00
				];
				qcom,mdss-dsi-on-command-state = "dsi_lp_mode";
				qcom,mdss-dsi-off-command-state = "dsi_hs_mode";
				qcom,mdss-dsi-h-sync-pulse = <0>;
				qcom,compression-mode = "dsc";
				qcom,mdss-dsc-slice-height = <20>;
				qcom,mdss-dsc-slice-width = <540>;
				qcom,mdss-dsc-slice-per-pkt = <2>;
				qcom,mdss-dsc-bit-per-component = <8>;
				qcom,mdss-dsc-bit-per-pixel = <8>;
				qcom,mdss-dsc-block-prediction-enable;
			};

			timing@1 {
				qcom,mdss-dsi-panel-framerate = <90>;
				qcom,mdss-dsi-panel-width = <1080>;
				qcom,mdss-dsi-panel-height = <2400>;
				qcom,mdss-dsi-h-front-porch = <16>;
				qcom,mdss-dsi-h-back-porch = <8>;
				qcom,mdss-dsi-h-pulse-width = <8>;
				qcom,mdss-dsi-h-sync-skew = <0>;
				qcom,mdss-dsi-v-back-porch = <8>;
				qcom,mdss-dsi-v-front-porch = <28>;
				qcom,mdss-dsi-v-pulse-width = <8>;
				qcom,mdss-dsi-h-left-border = <0>;
				qcom,mdss-dsi-h-right-border = <0>;
				qcom,mdss-dsi-v-top-border = <0>;
				qcom,mdss-dsi-v-bottom-border = <0>;
				//qcom,mdss-dsi-panel-jitter = <0x4 0x1>;
				qcom,mdss-dsi-timing-switch-command = [39 01 00 00 05 00 02 70 01];
				qcom,mdss-dsi-timing-switch-command-state = "dsi_lp_mode";
				qcom,mdss-dsi-on-command = [
					39 01 00 00 00 00 03 F0 3C 3C
					39 01 00 00 00 00 03 F1 3C 3C
					39 01 00 00 00 00 03 FF 3C 00
					39 01 00 00 00 00 05 D0 00 00 00 00
					39 01 00 00 00 00 04 B4 00 00 00
					39 01 00 00 00 00 09 B5 00 40 0A 00 00 C0 0A 00
					39 01 00 00 00 00 03 B7 21 76
					39 01 00 00 00 00 10 C1 02 0C 10 10 44 20 00 00 00 00 00 08 00 00 85
					39 01 00 00 00 00 03 FF 3C 01
					39 01 00 00 00 00 06 B0 50 10 10 15 00
					39 01 00 00 00 00 3B B1 C4 60 09 38 04 D0 02 00 00 00 01 03 00 10 09 60 00 12 00 12 00 10 03 0C 00 12 00 12 00 10 00 10 00 10 00 10 00 10 09 60 00 12 00 12 00 10 00 00 37 04 00 00 5F 09 00 00 FF 00
					39 01 00 00 00 00 17 B2 14 14 03 04 03 04 03 04 07 13 14 14 03 04 03 04 03 04 13 14 14 03
					39 01 00 00 00 00 1B B3 40 01 38 A5 C9 00 30 01 C0 A6 41 00 01 00 00 00 00 11 20 44 35 77 86 AA 9B FF
					39 01 00 00 00 00 06 B4 32 22 26 56 12
					39 01 00 00 00 00 13 B5 00 00 00 00 00 00 04 F0 20 00 00 00 00 00 00 00 00 00
					39 01 00 00 00 00 31 B7 00 FB FC 00 00 00 00 00 00 00 00 00 00 00 00 00 00 00 00 00 00 00 00 00 00 00 00 00 00 00 00 00 00 00 00 00 00 00 00 00 00 00 00 00 00 00 00 00
					39 01 00 00 00 00 0A B8 09 AA 55 AA 55 AA 55 AA 55
					39 01 00 00 00 00 29 BA 24 00 27 00 26 00 0C 00 0B 00 01 00 37 37 37 37 24 00 27 00 26 00 0C 00 0B 00 01 00 37 37 37 37 00 00 00 00 00 00 00 00
					39 01 00 00 00 00 19 BB 00 02 00 00 00 2B 00 00 00 00 79 79 00 00 79 79 00 00 79 79 00 00 79 79
					39 01 00 00 00 00 1B BC 83 01 00 07 00 09 00 0A 00 0C 00 0D 00 0F 00 E6 00 00 E6 00 00 E6 00 00 E6 00
					39 01 00 00 00 00 13 BE 03 00 00 0E 04 00 12 12 00 12 12 00 12 12 00 12 12 00
					39 01 00 00 00 00 12 C0 11 01 00 10 10 64 14 10 64 14 10 64 14 10 64 14 FF
					39 01 00 00 00 00 12 C5 21 02 00 31 00 12 AA 00 12 AA 00 12 AA 00 12 AA FF
					39 01 00 00 00 00 11 C7 66 00 66 00 66 00 00 00 00 66 00 11 00 00 00 00
					39 01 00 00 00 00 32 C8 00 00 00 00 00 00 00 00 06 06 06 00 60 10 00 00 00 00 06 20 00 00 00 00 00 00 00 00 00 00 00 00 00 00 00 00 00 00 00 00 00 00 00 00 00 00 00 00 FF
					39 01 00 00 00 00 63 C9 00 00 25 21 36 00 00 00 56 11 00 00 00 00 00 00 00 00 00 00 00 00 00 00 25 31 26 00 00 00 56 11 00 00 00 00 00 00 00 00 00 00 00 00 00 00 35 12 36 56 12 00 00 00 00 00 00 00 00 00 00 00 00 00 00 00 00 00 00 00 00 35 22 26 00 00 00 56 12 00 00 00 00 00 00 00 00 00 00 00 00 00 00 35 21 26 56 11
					39 01 00 00 00 00 17 CE 01 30 03 03 03 03 03 03 03 03 00 00 02 02 02 00 00 00 00 00 00 FF
					39 01 00 00 00 00 03 FF 3C 02
					39 01 00 00 00 00 1F B0 19 88 08 70 00 54 1E 1E 19 1E 41 10 1E 00 38 77 6C 6C 33 33 33 33 73 33 33 33 32 04 F0 33
					39 01 00 00 00 00 1F B1 09 88 08 6E 00 54 1E 1E 19 1E 41 10 1E 00 38 77 6C 6C 33 33 33 33 73 33 33 33 32 04 F0 33
					39 01 00 00 00 00 2C B2 00 00 77 19 21 29 01 03 05 07 07 08 09 0A 0D 0F 21 25 25 1C 00 77 19 21 29 01 03 05 07 08 09 0A 0B 0D 0F 25 21 21 00 00 00 00 FF
					39 01 00 00 00 00 29 B3 00 00 00 00 01 01 02 03 03 07 04 04 05 06 07 07 08 08 09 09 09 09 09 8B 8C 09 0A 09 0B 0C 0C 0C 00 0E 18 1C 00 00 21 00
					39 01 00 00 00 00 29 B3 00 00 00 00 01 01 02 03 03 07 04 04 05 06 07 07 08 08 09 09 09 09 09 8B 8C 09 0A 09 0B 0C 0C 0C 00 0E 14 18 00 00 21 00
					39 01 00 00 00 00 17 B4 BB BB B0 AA 9A 88 88 78 77 77 77 77 77 77 77 88 08 EC 44 00 21 00
					39 01 00 00 00 00 17 B5 22 22 20 11 11 11 11 00 00 00 00 00 00 00 00 00 00 02 00 00 00 FF
					39 01 00 00 00 00 20 BA 0F 0F 0F 0F 0F 0F 0F 0F 0F 0F 0F 0F 14 15 16 17 18 19 19 19 19 19 19 19 0F 0F 0F 19 19 19 00
					39 01 00 00 00 00 03 FF 3C 03
					39 01 00 00 00 00 A7 B0 00 00 FF 05 00 00 00 00 00 00 98 03 E8 03 1D 04 9A 03 E8 03 1F 04 9F 03 E9 03 24 04 A4 03 EA 03 29 04 A9 03 EB 03 2E 04 AE 03 EC 03 33 04 B3 03 ED 03 38 04 B8 03 EE 03 3D 04 BD 03 EF 03 42 04 C2 03 F0 03 47 04 C7 03 F1 03 4C 04 D2 03 F4 03 56 04 DD 03 F7 03 60 04 E8 03 FA 03 6A 04 FF 03 00 04 7F 04 16 04 06 04 94 04 2D 04 0C 04 A9 04 44 04 12 04 BE 04 44 04 12 04 BE 04 56 04 18 04 CB 04 5F 04 18 04 D2 04 5F 04 18 04 D2 04 91 04 3E 04 08 05 91 04 3E 04 08 05 91 04 3E 04 08 05 91 04 3E 04 08 05
					39 01 00 00 00 00 A7 B1 00 00 FF 05 00 00 00 00 00 00 44 03 36 03 B4 03 0C 04 FE 03 7C 04 70 04 62 04 E0 04 95 04 80 04 18 05 AB 04 94 04 3A 05 C7 04 9F 04 52 05 06 05 D0 04 90 05 10 05 D0 04 98 05 21 05 DB 04 AC 05 37 05 EB 04 C7 05 4B 05 FA 04 DB 05 69 05 0E 05 FB 05 8E 05 2A 05 21 06 AB 05 43 05 42 06 DD 05 6D 05 79 06 11 06 9B 05 B2 06 41 06 C7 05 E6 06 6B 06 EB 05 16 07 98 06 15 06 47 07 BC 06 37 06 71 07 E0 06 58 06 99 07 0C 07 82 06 CE 07 25 07 9B 06 E7 07 3F 07 B2 06 04 08 5C 07 CC 06 27 08 7C 07 EC 06 49 08
					39 01 00 00 00 00 A7 B2 00 00 FF 05 00 00 00 00 00 00 9B 03 84 01 00 00 78 04 67 04 0B 05 78 04 67 04 0B 05 B5 04 88 04 3A 05 D4 04 A2 04 5B 05 F1 04 B6 04 7D 05 39 05 EF 04 C3 05 44 05 F4 04 D2 05 5F 05 07 05 F0 05 7A 05 1C 05 0C 06 92 05 30 05 26 06 B4 05 4A 05 4B 06 DE 05 6E 05 78 06 04 06 8F 05 A2 06 3F 06 C5 05 E4 06 79 06 F9 05 26 07 AF 06 2A 06 63 07 E3 06 5C 06 9D 07 10 07 86 06 D1 07 39 07 AC 06 02 08 60 07 D2 06 2E 08 84 07 F3 06 58 08 AA 07 17 07 83 08 CC 07 36 07 AA 08 EB 07 53 07 CE 08 11 08 70 07 F4 08
					39 01 00 00 00 00 A7 B3 00 00 FF 05 00 00 00 00 00 00 89 03 C5 03 7A 01 EF 03 5F 04 55 02 83 04 6E 04 14 05 D2 04 93 04 54 05 F1 04 B1 04 7F 05 1B 05 D0 04 AB 05 67 05 11 05 F6 05 79 05 1D 05 0B 06 98 05 33 05 2C 06 B2 05 4C 05 48 06 CE 05 62 05 67 06 F7 05 85 05 95 06 24 06 AE 05 C6 06 4D 06 D3 05 F4 06 90 06 0F 06 41 07 D2 06 4C 06 8A 07 0E 07 85 06 CD 07 42 07 B6 06 0B 08 76 07 E5 06 47 08 A4 07 13 07 7C 08 CE 07 38 07 AD 08 F6 07 5E 07 DB 08 20 08 85 07 0C 09 46 08 A8 07 37 09 6A 08 CA 07 62 09 90 08 EA 07 90 09
					39 01 00 00 00 00 A7 B4 00 00 FF 05 00 00 00 00 00 00 E6 03 F1 03 8B 04 4A 04 55 04 EF 04 9C 04 71 04 21 05 E1 04 A6 04 6C 05 17 05 C9 04 A5 05 46 05 ED 04 D6 05 97 05 38 05 2A 06 AC 05 44 05 41 06 D2 05 65 05 6A 06 EE 05 7F 05 89 06 0C 06 99 05 AA 06 3A 06 C2 05 DF 06 6B 06 EF 05 16 07 99 06 19 06 4A 07 E4 06 5E 06 9E 07 29 07 9F 06 EE 07 68 07 DB 06 37 08 9F 07 0D 07 78 08 DD 07 49 07 BD 08 0C 08 73 07 F5 08 3B 08 9E 07 2D 09 6A 08 C7 07 64 09 99 08 F4 07 9B 09 C3 08 1A 08 CD 09 ED 08 3F 08 FF 09 19 09 65 08 32 0A
					39 01 00 00 00 00 A7 B5 00 00 FF 05 00 00 00 00 00 00 F6 03 ED 03 8C 04 5A 04 51 04 F0 04 9E 04 73 04 2B 05 F2 04 B2 04 82 05 2E 05 DA 04 BE 05 61 05 02 05 F2 05 B3 05 4D 05 48 06 C9 05 5E 05 61 06 ED 05 7F 05 88 06 0F 06 9C 05 AE 06 2F 06 B9 05 D0 06 60 06 E6 05 0A 07 95 06 16 06 44 07 C4 06 41 06 7B 07 0E 07 85 06 D2 07 5D 07 D0 06 28 08 9D 07 0D 07 74 08 D8 07 43 07 BA 08 15 08 7C 07 00 09 4B 08 AD 07 40 09 7F 08 DB 07 7D 09 AF 08 09 08 B6 09 E2 08 36 08 F1 09 11 09 5F 08 29 0A 3F 09 87 08 5F 0A 70 09 B2 08 99 0A
					39 01 00 00 00 00 A7 B6 00 00 FF 05 00 00 00 00 00 00 01 00 B8 03 F2 04 5E 04 50 04 F2 04 A6 04 77 04 31 05 FF 04 B8 04 8C 05 3C 05 E3 04 CD 05 71 05 0D 05 03 06 C4 05 5D 05 5B 06 DC 05 71 05 75 06 FF 05 8F 05 9C 06 23 06 AF 05 C3 06 43 06 CC 05 E7 06 76 06 FA 05 22 07 AC 06 2B 06 5F 07 E4 06 5F 06 9D 07 2B 07 A1 06 F1 07 77 07 E8 06 49 08 BA 07 27 07 96 08 F8 07 61 07 DF 08 38 08 9C 07 28 09 70 08 CE 07 6B 09 A5 08 FE 07 A9 09 D8 08 2C 08 E6 09 0E 09 5D 08 25 0A 3F 09 88 08 5F 0A 6F 09 B2 08 98 0A A2 09 DD 08 D4 0A
					39 01 00 00 00 00 A7 B7 00 00 FF 05 00 00 00 00 00 00 33 00 C1 03 EE 04 62 04 54 04 F6 04 B3 04 7E 04 3E 05 10 05 C2 04 9E 05 4F 05 F2 04 E1 05 85 05 1F 05 19 06 DA 05 70 05 73 06 F3 05 84 05 8F 06 1C 06 AA 05 BB 06 40 06 C9 05 E2 06 5F 06 E5 05 06 07 93 06 14 06 43 07 CB 06 48 06 82 07 05 07 7C 06 C2 07 4C 07 BF 06 18 08 A1 07 12 07 77 08 E1 07 4B 07 C3 08 24 08 8A 07 11 09 64 08 C4 07 5D 09 9E 08 F9 07 A1 09 D7 08 2B 08 E5 09 0D 09 5C 08 26 0A 46 09 8E 08 67 0A 7B 09 BC 08 A5 0A AE 09 E7 08 E3 0A E6 09 16 09 23 0B
					39 01 00 00 00 00 A7 B8 00 00 FF 05 00 00 00 00 00 00 44 04 43 04 9C 04 69 04 57 04 FB 04 C0 04 87 04 4B 05 22 05 CF 04 B2 05 63 05 03 05 F4 05 9D 05 33 05 33 06 F3 05 87 05 8E 06 11 06 A0 05 AF 06 38 06 C4 05 DB 06 5E 06 E5 05 04 07 7E 06 01 06 2A 07 B5 06 34 06 69 07 F1 06 6C 06 AB 07 1F 07 97 06 E3 07 76 07 E7 06 48 08 C6 07 32 07 A4 08 11 08 78 07 F9 08 54 08 B4 07 49 09 98 08 F4 07 9A 09 D6 08 2B 08 E3 09 12 09 5F 08 2A 0A 4C 09 93 08 6D 0A 8A 09 C8 08 B5 0A C2 09 F8 08 F9 0A FA 09 27 09 3B 0B 37 0A 5B 09 80 0B
					39 01 00 00 00 00 A7 B9 00 00 FF 05 00 00 00 00 00 00 42 04 38 04 01 05 80 04 57 04 01 05 D8 04 8F 04 5C 05 3B 05 E0 04 CA 05 7E 05 18 05 11 06 BB 05 4E 05 53 06 12 06 A3 05 AF 06 32 06 BC 05 D2 06 5B 06 E1 05 00 07 7F 06 04 06 2B 07 A2 06 24 06 53 07 E0 06 5D 06 98 07 1A 07 91 06 DB 07 4B 07 C1 06 16 08 A7 07 15 07 80 08 FA 07 63 07 E0 08 48 08 AB 07 3B 09 90 08 EC 07 91 09 DA 08 2F 08 E7 09 1C 09 6A 08 35 0A 5E 09 A1 08 83 0A 9D 09 D9 08 CD 0A E1 09 13 09 1C 0B 1F 0A 47 09 66 0B 5E 0A 7D 09 AC 0B A1 0A B5 09 FA 0B
					39 01 00 00 00 00 A7 BA 00 00 FF 05 00 00 00 00 00 00 41 04 2E 04 0E 05 7B 04 64 04 0E 05 FA 04 A7 04 7E 05 62 05 01 05 F4 05 AD 05 42 05 44 06 EE 05 7B 05 8C 06 4A 06 D5 05 EE 06 6C 06 F2 05 15 07 98 06 1A 06 46 07 C1 06 3F 06 74 07 E6 06 63 06 9E 07 26 07 9E 06 E8 07 65 07 DA 06 31 08 9D 07 0D 07 73 08 FE 07 65 07 E5 08 59 08 BA 07 4F 09 B0 08 08 08 B4 09 00 09 4F 08 14 0A 54 09 9B 08 76 0A A1 09 DB 08 D4 0A EE 09 1D 09 2D 0B 3A 0A 5D 09 85 0B 88 0A A0 09 DC 0B D6 0A E0 09 3E 0C 23 0B 20 0A 92 0C 74 0B 66 0A F5 0C
					39 01 00 00 00 00 A7 BB 00 00 FF 05 00 00 00 00 00 00 50 04 45 04 DD 04 86 04 68 04 17 05 1C 05 B7 04 B0 05 80 05 1B 05 14 06 D1 05 62 05 6C 06 13 06 9E 05 B3 06 72 06 FA 05 19 07 95 06 18 06 43 07 C3 06 43 06 76 07 EF 06 6A 06 A8 07 17 07 91 06 D4 07 58 07 CC 06 23 08 99 07 0A 07 6D 08 D7 07 43 07 B4 08 3D 08 A0 07 2D 09 A1 08 FB 07 A3 09 FB 08 4B 08 0D 0A 57 09 9C 08 79 0A B2 09 E9 08 E6 0A 08 0A 33 09 4B 0B 5F 0A 7B 09 AE 0B B5 0A C4 09 12 0C 10 0B 11 0A 7D 0C 69 0B 5B 0A E6 0C C4 0B A8 0A 54 0D 2B 0C FE 0A D7 0D
					39 01 00 00 00 00 A7 C0 00 00 FF 05 00 00 00 00 00 00 F2 03 03 04 8D 04 F3 03 03 04 8D 04 F5 03 04 04 8E 04 F7 03 05 04 8F 04 F9 03 06 04 90 04 FB 03 07 04 91 04 FD 03 08 04 92 04 FF 03 09 04 93 04 01 04 0A 04 94 04 03 04 0B 04 95 04 05 04 0C 04 96 04 0A 04 0E 04 99 04 0F 04 10 04 9C 04 14 04 12 04 9F 04 1E 04 16 04 A6 04 28 04 1A 04 AD 04 32 04 1E 04 B4 04 3C 04 22 04 BB 04 46 04 26 04 C2 04 50 04 2A 04 C9 04 5A 04 2A 04 D2 04 69 04 2C 04 DF 04 69 04 2C 04 DF 04 87 04 3C 04 FB 04 87 04 3C 04 FB 04 87 04 3C 04 FB 04
					39 01 00 00 00 00 A7 C1 00 00 FF 05 00 00 00 00 00 00 42 03 01 00 25 01 42 03 01 00 25 01 42 03 01 00 5C 05 CF 04 BE 04 5C 05 CF 04 BE 04 5C 05 E4 04 C9 04 72 05 10 05 F2 04 9D 05 20 05 F2 04 AC 05 33 05 FC 04 BF 05 45 05 07 05 D5 05 56 05 12 05 E7 05 72 05 21 05 03 06 92 05 3A 05 26 06 B3 05 53 05 4A 06 E3 05 78 05 7E 06 13 06 A2 05 B3 06 41 06 CA 05 E6 06 6B 06 EF 05 16 07 97 06 18 06 46 07 BC 06 39 06 70 07 DF 06 59 06 97 07 0A 07 82 06 CC 07 23 07 9B 06 E5 07 3E 07 B4 06 05 08 5C 07 CD 06 23 08 79 07 EA 06 47 08
					39 01 00 00 00 00 A7 C2 00 00 FF 05 00 00 00 00 00 00 45 04 35 04 C4 04 A2 04 93 04 2F 05 A2 04 93 04 2F 05 D3 04 B2 04 64 05 E9 04 C7 04 75 05 05 05 D6 04 94 05 4A 05 0D 05 D7 05 52 05 0E 05 DF 05 69 05 1D 05 FC 05 82 05 30 05 14 06 99 05 40 05 2E 06 BA 05 58 05 52 06 E4 05 7A 05 7F 06 06 06 98 05 A5 06 3F 06 C9 05 E5 06 79 06 FC 05 27 07 AE 06 2B 06 62 07 E3 06 5D 06 9C 07 0F 07 87 06 D1 07 39 07 AD 06 01 08 60 07 D3 06 2D 08 89 07 F9 06 5B 08 A9 07 18 07 83 08 CA 07 35 07 A8 08 E9 07 52 07 CD 08 10 08 77 07 F6 08
					39 01 00 00 00 00 A7 C3 00 00 FF 05 00 00 00 00 00 00 00 00 2E 04 D7 04 00 00 99 04 D7 04 AA 04 99 04 39 05 DF 04 BC 04 6C 05 06 05 D3 04 94 05 29 05 E8 04 B9 05 73 05 28 05 03 06 80 05 2E 05 12 06 9E 05 42 05 33 06 B9 05 58 05 51 06 D5 05 6F 05 6E 06 FA 05 8E 05 97 06 26 06 B4 05 C8 06 4F 06 D8 05 F6 06 90 06 10 06 40 07 D1 06 4D 06 8B 07 0D 07 84 06 CB 07 3F 07 B3 06 08 08 78 07 E9 06 47 08 A6 07 14 07 7C 08 CC 07 37 07 AA 08 F4 07 5B 07 D9 08 1E 08 82 07 09 09 43 08 A5 07 35 09 67 08 C5 07 60 09 8F 08 EB 07 8F 09
					39 01 00 00 00 00 A7 C5 00 00 FF 05 00 00 00 00 00 00 9A 04 00 00 0E 05 B8 04 00 00 43 05 B8 04 99 04 43 05 FF 04 C7 04 86 05 25 05 E5 04 B5 05 52 05 04 05 E4 05 9E 05 49 05 32 06 B1 05 53 05 47 06 D1 05 6D 05 6A 06 F0 05 87 05 8C 06 0E 06 A0 05 AC 06 3B 06 C6 05 DF 06 6C 06 F4 05 15 07 99 06 1B 06 49 07 E0 06 5C 06 9A 07 26 07 9E 06 EB 07 66 07 D9 06 33 08 9D 07 0C 07 75 08 DB 07 48 07 BA 08 0A 08 71 07 F2 08 39 08 9C 07 29 09 67 08 C5 07 5F 09 96 08 F1 07 96 09 C1 08 18 08 C9 09 EA 08 3D 08 FA 09 16 09 64 08 30 0A
					39 01 00 00 00 00 A7 C6 00 00 FF 05 00 00 00 00 00 00 A4 04 12 00 0B 05 BD 04 2B 00 24 05 C8 04 99 04 4B 05 05 05 CE 04 94 05 38 05 F0 04 C9 05 67 05 13 05 F9 05 B7 05 5B 05 4E 06 D3 05 6E 05 6C 06 F0 05 87 05 8C 06 14 06 A8 05 B3 06 30 06 BE 05 D2 06 60 06 E9 05 09 07 94 06 18 06 43 07 C4 06 43 06 7A 07 11 07 8A 06 D1 07 5B 07 D0 06 26 08 9B 07 0C 07 71 08 D6 07 43 07 B7 08 16 08 7F 07 FF 08 4C 08 AF 07 3C 09 7C 08 DA 07 78 09 AD 08 05 08 B3 09 E0 08 35 08 EE 09 0F 09 5E 08 25 0A 3B 09 85 08 57 0A 6E 09 AF 08 95 0A
					39 01 00 00 00 00 A7 C7 00 00 FF 05 00 00 00 00 00 00 34 04 15 04 CC 04 98 04 79 04 30 05 C2 04 9E 04 4F 05 0F 05 D6 04 9F 05 48 05 FC 04 DA 05 77 05 1F 05 0A 06 C9 05 69 05 5F 06 E0 05 7A 05 7A 06 04 06 99 05 A2 06 27 06 B7 05 C8 06 47 06 D4 05 EB 06 78 06 FE 05 23 07 AC 06 2D 06 5F 07 E4 06 60 06 9D 07 2C 07 A2 06 F2 07 76 07 E8 06 47 08 B8 07 26 07 94 08 F6 07 61 07 DD 08 37 08 9B 07 27 09 6D 08 CD 07 68 09 A2 08 FC 07 A6 09 D6 08 2B 08 E2 09 0B 09 5A 08 21 0A 3D 09 86 08 5C 0A 6D 09 B0 08 94 0A A0 09 DB 08 D4 0A
					39 01 00 00 00 00 A7 C8 00 00 FF 05 00 00 00 00 00 00 46 04 5A 04 1F 05 9E 04 7A 04 34 05 CC 04 A3 04 57 05 1C 05 DE 04 AD 05 57 05 07 05 E7 05 8A 05 2E 05 1F 06 DF 05 7C 05 77 06 F5 05 8C 05 91 06 1A 06 AC 05 BA 06 3D 06 CB 05 E1 06 5F 06 E8 05 06 07 96 06 1A 06 45 07 C8 06 47 06 7F 07 01 07 7A 06 BF 07 49 07 BD 06 15 08 9A 07 0B 07 71 08 E0 07 4B 07 C1 08 20 08 86 07 0D 09 62 08 C3 07 5B 09 9C 08 F8 07 9F 09 D2 08 27 08 DE 09 0A 09 59 08 22 0A 44 09 8C 08 64 0A 78 09 B9 08 A1 0A AC 09 E6 08 DE 0A E2 09 13 09 1F 0B
					39 01 00 00 00 00 A7 C9 00 00 FF 05 00 00 00 00 00 00 94 04 24 04 C1 04 94 04 86 04 24 05 D6 04 AA 04 63 05 2D 05 E8 04 BE 05 6C 05 16 05 FE 05 A1 05 3F 05 38 06 F6 05 8F 05 90 06 10 06 A4 05 AF 06 37 06 C7 05 DA 06 5E 06 E8 05 04 07 7E 06 04 06 29 07 B4 06 35 06 67 07 ED 06 69 06 A8 07 1E 07 98 06 E1 07 74 07 E6 06 45 08 C4 07 31 07 A2 08 0D 08 75 07 F6 08 51 08 B2 07 46 09 95 08 F1 07 96 09 D3 08 29 08 E0 09 0F 09 5C 08 27 0A 49 09 90 08 6A 0A 86 09 C5 08 B1 0A BF 09 F7 08 F5 0A F7 09 24 09 37 0B 30 0A 57 09 7A 0B
					39 01 00 00 00 00 A7 CA 00 00 FF 05 00 00 00 00 00 00 4A 04 3B 04 2A 05 97 04 89 04 2A 05 E4 04 B2 04 72 05 43 05 F8 04 D5 05 85 05 29 05 1A 06 BC 05 56 05 56 06 13 06 AA 05 B0 06 33 06 C1 05 D5 06 59 06 E3 05 FF 06 80 06 07 06 2C 07 A2 06 26 06 52 07 DD 06 5C 06 95 07 17 07 90 06 D8 07 4C 07 C3 06 16 08 A5 07 16 07 7C 08 F7 07 61 07 DD 08 45 08 A8 07 37 09 8D 08 E9 07 8D 09 D7 08 2C 08 E4 09 19 09 66 08 31 0A 5A 09 9F 08 7E 0A 9A 09 D6 08 C9 0A DE 09 10 09 18 0B 1C 0A 44 09 63 0B 5A 0A 79 09 AB 0B 9D 0A B2 09 F8 0B
					39 01 00 00 00 00 A7 CB 00 00 FF 05 00 00 00 00 00 00 7B 04 6F 04 24 05 A2 04 8F 04 32 05 07 05 C3 04 8F 05 6A 05 14 05 FB 05 B4 05 50 05 4D 06 F0 05 83 05 8E 06 4D 06 DB 05 EF 06 6D 06 F6 05 14 07 98 06 1D 06 45 07 C1 06 42 06 75 07 E7 06 64 06 9F 07 24 07 9D 06 E7 07 63 07 D8 06 2F 08 9B 07 0B 07 71 08 FC 07 63 07 E2 08 57 08 B8 07 4D 09 AD 08 06 08 B2 09 FC 08 4C 08 11 0A 51 09 97 08 73 0A 9F 09 DA 08 CE 0A EB 09 1A 09 2A 0B 37 0A 5A 09 82 0B 86 0A 9E 09 DE 0B D3 0A DD 09 37 0C 20 0B 1D 0A 8F 0C 71 0B 61 0A F8 0C
					39 01 00 00 00 00 A7 CC 00 00 FF 05 00 00 00 00 00 00 B2 04 6F 02 1E 00 B3 04 93 04 22 05 0E 05 D2 04 A5 05 87 05 2A 05 1B 06 D4 05 6C 05 6F 06 14 06 A3 05 B7 06 73 06 FD 05 1A 07 96 06 1C 06 43 07 C3 06 44 06 77 07 EE 06 6D 06 A7 07 17 07 92 06 D5 07 57 07 CD 06 23 08 98 07 0A 07 6D 08 D5 07 41 07 B4 08 3A 08 9D 07 2A 09 9D 08 F8 07 A0 09 F8 08 49 08 0A 0A 53 09 97 08 75 0A AF 09 E8 08 E1 0A 05 0A 30 09 48 0B 5A 0A 78 09 AB 0B B1 0A C0 09 0D 0C 0C 0B 0D 0A 78 0C 65 0B 57 0A E3 0C BF 0B A4 0A 52 0D 29 0C FC 0A D2 0D
					39 01 00 00 00 00 A7 D0 00 00 FF 05 00 00 00 00 00 00 35 04 57 04 9E 04 35 04 57 04 9F 04 36 04 57 04 A1 04 37 04 57 04 A3 04 38 04 57 04 A5 04 39 04 57 04 A7 04 3A 04 57 04 A9 04 3B 04 57 04 AB 04 3C 04 57 04 AD 04 3D 04 57 04 AF 04 3E 04 57 04 B1 04 41 04 57 04 B5 04 44 04 57 04 B9 04 47 04 57 04 BD 04 4E 04 57 04 C5 04 55 04 57 04 CD 04 5C 04 57 04 D5 04 63 04 57 04 DD 04 6A 04 57 04 E5 04 71 04 57 04 ED 04 79 04 57 04 EF 04 85 04 58 04 FB 04 85 04 58 04 FB 04 8F 04 58 04 06 05 91 04 58 04 07 05 9A 04 59 04 0A 05
					39 01 00 00 00 00 A7 D1 00 00 FF 05 00 00 00 00 00 00 A8 04 B0 04 34 05 AF 04 B4 04 3B 05 BE 04 BC 04 4A 05 CD 04 C4 04 59 05 DC 04 CC 04 68 05 EB 04 D4 04 77 05 FC 04 DD 04 89 05 0A 05 E4 04 97 05 1A 05 EC 04 A9 05 2F 05 F8 04 BE 05 3D 05 00 05 CD 05 60 05 17 05 F2 05 7F 05 2E 05 13 06 9D 05 44 05 33 06 D7 05 70 05 73 06 06 06 99 05 A7 06 33 06 BF 05 D9 06 5C 06 E2 05 08 07 84 06 06 06 34 07 A8 06 27 06 5D 07 CB 06 46 06 85 07 EC 06 65 06 AB 07 0A 07 7F 06 CC 07 27 07 9B 06 EE 07 42 07 B5 06 0D 08 58 07 CE 06 2F 08
					39 01 00 00 00 00 A7 D2 00 00 FF 05 00 00 00 00 00 00 9A 04 98 04 2C 05 A7 04 A2 04 38 05 C2 04 B6 04 50 05 DD 04 CA 04 68 05 F1 04 D5 04 7E 05 07 05 DF 04 96 05 21 05 F0 04 B1 05 37 05 FA 04 C6 05 4F 05 09 05 E2 05 64 05 18 05 F7 05 7C 05 29 05 10 06 A6 05 4A 05 3D 06 CC 05 69 05 68 06 F0 05 85 05 8F 06 32 06 BD 05 D8 06 6E 06 F3 05 1B 07 9F 06 1F 06 54 07 D0 06 4C 06 8B 07 FC 06 74 06 BE 07 25 07 9B 06 ED 07 4C 07 BF 06 19 08 6F 07 E0 06 43 08 91 07 FE 06 6A 08 B3 07 1F 07 92 08 D1 07 39 07 B5 08 F1 07 57 07 DB 08
					39 01 00 00 00 00 A7 D3 00 00 FF 05 00 00 00 00 00 00 62 04 6E 04 C3 04 B3 04 A8 04 2D 05 CA 04 BA 04 58 05 ED 04 CA 04 7E 05 05 05 DE 04 98 05 27 05 EE 04 B7 05 47 05 06 05 D8 05 60 05 14 05 F4 05 7E 05 2A 05 15 06 99 05 3F 05 30 06 B2 05 52 05 4A 06 E3 05 7B 05 81 06 0F 06 A0 05 B1 06 38 06 C3 05 E0 06 81 06 04 06 32 07 C3 06 42 06 7B 07 FC 06 74 06 BD 07 31 07 A6 06 F9 07 61 07 D2 06 32 08 91 07 01 07 6A 08 B7 07 22 07 95 08 E0 07 48 07 C4 08 06 08 6B 07 F2 08 2B 08 8D 07 1D 09 4F 08 AE 07 48 09 75 08 D1 07 72 09
					39 01 00 00 00 00 A7 D4 00 00 FF 05 00 00 00 00 00 00 76 04 4F 04 E6 04 76 04 A9 04 42 05 D1 04 BD 04 5E 05 FA 04 D5 04 88 05 22 05 EB 04 B3 05 49 05 05 05 DA 05 71 05 20 05 04 06 90 05 37 05 26 06 B3 05 51 05 4D 06 D2 05 6C 05 6F 06 EE 05 82 05 8B 06 24 06 B2 05 C8 06 54 06 DD 05 FE 06 82 06 04 06 32 07 D2 06 50 06 8D 07 18 07 8F 06 DC 07 56 07 CA 06 25 08 8F 07 FF 06 67 08 C4 07 2F 07 A4 08 F8 07 62 07 E1 08 25 08 88 07 15 09 52 08 B1 07 4A 09 80 08 DA 07 7F 09 AA 08 00 08 B1 09 D3 08 25 08 E3 09 FE 08 49 08 17 0A
					39 01 00 00 00 00 A7 D5 00 00 FF 05 00 00 00 00 00 00 08 00 46 04 5D 00 6C 00 AA 04 C1 00 D3 04 BB 04 64 05 07 05 D5 04 96 05 34 05 F3 04 C7 05 5F 05 12 05 F1 05 8B 05 32 05 20 06 AD 05 4C 05 45 06 D0 05 6A 05 6D 06 F2 05 87 05 90 06 11 06 A0 05 B2 06 49 06 D3 05 F3 06 7D 06 01 06 2C 07 AD 06 2B 06 63 07 01 07 7A 06 C3 07 49 07 BE 06 18 08 89 07 FA 06 61 08 C8 07 33 07 A9 08 01 08 66 07 EB 08 3A 08 9B 07 2A 09 68 08 C4 07 63 09 99 08 F0 07 9D 09 C9 08 1C 08 D7 09 F7 08 44 08 0D 0A 25 09 6C 08 43 0A 53 09 94 08 7A 0A
					39 01 00 00 00 00 A7 D6 00 00 FF 05 00 00 00 00 00 00 49 04 40 04 D3 04 AD 04 A4 04 37 05 D9 04 BE 04 6A 05 0F 05 DC 04 9F 05 3E 05 FC 04 D0 05 6D 05 1C 05 01 06 99 05 3D 05 30 06 BD 05 5A 05 57 06 E3 05 79 05 80 06 08 06 97 05 A8 06 24 06 B2 05 C8 06 5E 06 E6 05 0B 07 93 06 16 06 46 07 C3 06 43 06 7C 07 1C 07 94 06 E3 07 65 07 D8 06 38 08 A8 07 16 07 85 08 E9 07 54 07 CE 08 23 08 87 07 14 09 59 08 B8 07 53 09 8E 08 E7 07 91 09 C1 08 15 08 CD 09 F3 08 42 08 09 0A 24 09 6C 08 42 0A 53 09 96 08 7F 0A 81 09 BF 08 B7 0A
					39 01 00 00 00 00 A7 D7 00 00 FF 05 00 00 00 00 00 00 AB 04 01 00 2F 05 E0 04 01 00 4F 05 E0 04 C2 04 71 05 1B 05 E5 04 AB 05 4F 05 07 05 E2 05 7F 05 2A 05 14 06 AE 05 4E 05 47 06 D3 05 6C 05 6F 06 FA 05 8D 05 99 06 1D 06 AB 05 C1 06 3D 06 C9 05 E6 06 7B 06 FF 05 2A 07 B1 06 30 06 68 07 EA 06 63 06 A8 07 3C 07 B1 06 09 08 8A 07 FB 06 62 08 CF 07 3A 07 B2 08 11 08 76 07 FE 08 4E 08 AD 07 47 09 88 08 E3 07 8B 09 C0 08 14 08 CD 09 F6 08 44 08 0D 0A 2B 09 73 08 4C 0A 60 09 A0 08 88 0A 94 09 CC 08 C7 0A C6 09 F6 08 07 0B
					39 01 00 00 00 00 A7 D8 00 00 FF 05 00 00 00 00 00 00 AD 04 00 00 41 05 B4 04 A8 04 41 05 EA 04 C7 04 7A 05 2A 05 F0 04 BA 05 61 05 14 05 F5 05 98 05 3D 05 2F 06 C9 05 63 05 63 06 EC 05 82 05 8B 06 15 06 A5 05 B8 06 39 06 C5 05 E0 06 5B 06 E3 05 07 07 9E 06 1F 06 51 07 D7 06 54 06 91 07 09 07 83 06 CA 07 65 07 DA 06 35 08 B4 07 22 07 93 08 FD 07 64 07 E6 08 41 08 A2 07 38 09 82 08 DC 07 84 09 C2 08 16 08 CD 09 FB 08 4A 08 13 0A 35 09 7C 08 57 0A 6E 09 AD 08 9A 0A A7 09 DE 08 DD 0A DF 09 0E 09 1E 0B 18 0A 3C 09 62 0B
					39 01 00 00 00 00 A7 D9 00 00 FF 05 00 00 00 00 00 00 D0 00 CF 00 4F 05 BB 04 AA 04 51 05 FA 04 CE 04 87 05 3D 05 F9 04 D0 05 7C 05 27 05 12 06 B3 05 52 05 4B 06 E6 05 7D 05 84 06 0C 06 9D 05 AE 06 36 06 C4 05 DE 06 60 06 E8 05 0B 07 81 06 04 06 30 07 C5 06 44 06 7D 07 01 07 7B 06 C2 07 35 07 AC 06 FE 07 96 07 06 07 6D 08 E8 07 51 07 CE 08 35 08 98 07 29 09 7E 08 DA 07 80 09 C4 08 17 08 D1 09 06 09 53 08 1E 0A 48 09 8C 08 6B 0A 88 09 C2 08 B7 0A C7 09 F8 08 01 0B 04 0A 2C 09 4B 0B 43 0A 61 09 93 0B 83 0A 96 09 D8 0B
					39 01 00 00 00 00 A7 DE 00 00 FF 05 00 00 00 00 00 00 92 04 9A 04 32 05 C0 04 B0 04 51 05 0F 05 DD 04 9F 05 61 05 15 05 F5 05 A7 05 49 05 3F 06 E3 05 7A 05 80 06 1B 06 AB 05 BF 06 46 06 D0 05 EE 06 76 06 FB 05 24 07 9F 06 20 06 53 07 C3 06 43 06 7D 07 0B 07 84 06 CE 07 4A 07 BF 06 16 08 83 07 F4 06 59 08 EA 07 53 07 D3 08 47 08 A8 07 3D 09 9D 08 F5 07 A3 09 EE 08 3F 08 02 0A 3E 09 84 08 60 0A 8C 09 C5 08 BD 0A D7 09 05 09 16 0B 22 0A 45 09 6D 0B 6E 0A 84 09 C4 0B BA 0A C5 09 1D 0C 08 0B 04 0A 77 0C 54 0B 45 0A D4 0C
					39 01 00 00 00 00 A7 DF 00 00 FF 05 00 00 00 00 00 00 26 03 A1 04 05 05 C8 04 B4 04 58 05 24 05 E9 04 B5 05 7F 05 29 05 14 06 C7 05 62 05 62 06 06 06 99 05 A7 06 41 06 CD 05 EA 06 6F 06 F5 05 1C 07 A2 06 23 06 55 07 CA 06 49 06 85 07 F4 06 6E 06 B2 07 3D 07 B3 06 0A 08 7E 07 F0 06 53 08 BB 07 29 07 9B 08 2A 08 8E 07 1B 09 8E 08 E9 07 92 09 E8 08 38 08 FB 09 44 09 89 08 66 0A 9C 09 D4 08 D1 0A F1 09 1C 09 35 0B 47 0A 65 09 98 0B 9D 0A AD 09 FA 0B F6 0A F6 09 61 0C 4D 0B 3F 0A CA 0C AA 0B 8B 0A 39 0D 0C 0C DF 0A B5 0D
					39 01 00 00 00 00 A7 BD 00 00 FF 05 00 00 00 00 00 00 F9 00 00 00 09 01 E8 03 01 00 37 04 00 04 6F 00 92 04 00 04 6F 02 92 04 0B 04 FE 03 9C 04 2B 04 11 04 BA 04 51 04 28 04 E0 04 7D 04 43 04 10 05 8C 04 4D 04 20 05 8C 04 4D 04 20 05 A4 04 62 04 39 05 D2 04 87 04 6A 05 F0 04 9A 04 8B 05 0F 05 B3 04 AD 05 41 05 E1 04 E1 05 72 05 0C 05 14 06 AA 05 36 05 58 06 D3 05 5B 05 86 06 FC 05 7F 05 B4 06 20 06 A0 05 DE 06 43 06 C0 05 06 07 64 06 DE 05 2B 07 85 06 FD 05 51 07 A2 06 1A 06 72 07 C0 06 38 06 95 07 D9 06 4E 06 B1 07
					39 01 00 00 00 00 A7 BE 00 00 FF 05 00 00 00 00 00 00 F2 01 00 00 12 02 F0 03 01 00 56 04 00 04 9E 01 92 04 0C 04 FF 03 9D 04 3A 04 1A 04 C8 04 72 04 3C 04 04 05 8C 04 4D 04 20 05 95 04 55 04 29 05 C0 04 7C 04 57 05 D5 04 88 04 6E 05 E9 04 95 04 84 05 15 05 B8 04 B4 05 39 05 D8 04 DA 05 53 05 F5 04 EF 05 A3 05 2F 05 4F 06 DB 05 62 05 8F 06 12 06 93 05 CE 06 41 06 BE 05 04 07 6E 06 E7 05 36 07 99 06 11 06 67 07 C1 06 39 06 97 07 E4 06 57 06 BE 07 08 07 79 06 E6 07 2B 07 99 06 0C 08 46 07 B3 06 28 08 58 07 BF 06 4F 08
					39 01 00 00 00 00 A7 BF 00 00 FF 05 00 00 00 00 00 00 E4 03 01 00 25 04 00 04 01 00 92 04 00 04 F8 03 92 04 3C 04 1B 04 C9 04 8C 04 4D 04 20 05 8C 04 4D 04 20 05 C7 04 82 04 5E 05 DF 04 8D 04 79 05 FE 04 A5 04 9A 05 1B 05 BD 04 BA 05 35 05 D3 04 D7 05 59 05 FB 04 F4 05 96 05 24 05 41 06 C0 05 4A 05 70 06 0B 06 8D 05 C6 06 4C 06 C8 05 10 07 89 06 01 06 55 07 C0 06 38 06 95 07 F0 06 62 06 CB 07 23 07 92 06 04 08 48 07 B5 06 2A 08 60 07 C5 06 61 08 97 07 FF 06 8D 08 BD 07 21 07 B8 08 E2 07 43 07 E3 08 04 08 62 07 09 09
					39 01 00 00 00 00 A7 BC 00 00 FF 05 00 00 00 00 00 00 7E 02 8A 02 C6 03 D6 02 CC 02 1E 04 62 03 6D 03 AB 04 08 04 F9 03 64 05 89 04 67 04 EC 05 F3 04 C6 04 5C 06 5F 05 25 05 DD 06 A9 05 64 05 23 07 F2 05 A6 05 70 07 36 06 E1 05 B4 07 76 06 1A 06 F4 07 E3 06 7A 06 5F 08 46 07 D3 06 C0 08 A1 07 24 07 19 09 43 08 B4 07 B9 09 D4 08 33 08 53 0A 59 09 AA 08 E6 0A D7 09 18 09 73 0B 51 0A 83 09 FD 0B C2 0A E4 09 83 0C 34 0B 44 0A 03 0D A4 0B A2 0A 82 0D 17 0C 01 0B 03 0E 83 0C 5E 0B 82 0E F6 0C B9 0B 01 0F 67 0D 17 0C 82 0F
					39 01 00 00 00 00 A7 E4 00 00 FF 05 84 0D D4 0B EA 0F 84 0D D4 0B EA 0F 84 0D D4 0B EA 0F 84 0D D4 0B EA 0F 84 0D D4 0B EA 0F 84 0D D4 0B EA 0F 84 0D D4 0B EA 0F 84 0D D4 0B EA 0F 84 0D D4 0B EA 0F 84 0D D4 0B EA 0F 84 0D D4 0B EA 0F 84 0D D4 0B EA 0F 84 0D D4 0B EA 0F 84 0D D4 0B EA 0F 84 0D D4 0B EA 0F 84 0D D4 0B EA 0F 84 0D D4 0B EA 0F 84 0D D4 0B EA 0F 84 0D D4 0B EA 0F 84 0D D4 0B EA 0F 84 0D D4 0B EA 0F 84 0D D4 0B EA 0F 84 0D D4 0B EA 0F 84 0D D4 0B EA 0F 84 0D D4 0B EA 0F 84 0D D4 0B EA 0F 84 0D D4 0B EA 0F
					39 01 00 00 00 00 03 FF 3C 04
					39 01 00 00 00 00 2C B2 00 0A 77 66 55 44 33 22 11 11 10 00 00 00 00 00 FF 7E FE 7E FD 7D FD 7D FC 7C FC 7C FB BB 7B 3A 1A FA DA BB 99 79 59 38 18 08 FE
					39 01 00 00 00 00 09 B3 0C 02 3C 00 00 00 00 00
					39 01 00 00 00 00 03 FF 3C 05
					39 01 00 00 00 00 17 B1 F0 01 C0 08 22 02 7C 08 DE 60 00 00 00 00 00 00 00 00 00 00 00 00
					39 01 00 00 00 00 81 D0 11 00 00 89 30 80 09 60 04 38 00 14 02 1C 02 1C 02 00 02 0E 00 20 03 2E 00 07 00 0C 03 00 03 15 18 00 10 F0 03 0C 20 00 06 0B 0B 33 0E 1C 2A 38 46 54 62 69 70 77 79 7B 7D 7E 01 02 01 00 09 40 09 BE 19 FC 19 FA 19 F8 1A 38 1A 78 1A B6 2A F6 2B 34 2B 74 3B 74 6B F4 00 00 00 00 00 00 00 00 00 00 00 00 00 00 00 00 00 00 00 00 00 00 00 00 00 00 00 00 00 00 00 00 00 00 00 00 00 00 00 00
					39 01 00 00 00 00 81 D1 11 00 00 89 30 80 09 60 04 38 00 14 02 1C 02 1C 02 00 02 0E 00 20 03 2E 00 07 00 0C 03 00 03 15 18 00 10 F0 03 0C 20 00 06 0B 0B 33 0E 1C 2A 38 46 54 62 69 70 77 79 7B 7D 7E 01 02 01 00 09 40 09 BE 19 FC 19 FA 19 F8 1A 38 1A 78 1A B6 2A F6 2B 34 2B 74 3B 74 6B F4 00 00 00 00 00 00 00 00 00 00 00 00 00 00 00 00 00 00 00 00 00 00 00 00 00 00 00 00 00 00 00 00 00 00 00 00 00 00 00 00
					39 01 00 00 00 00 03 FF 3C 0A
					39 01 00 00 00 00 15 B0 00 00 10 00 00 00 00 00 00 00 00 00 00 00 00 00 00 00 00 00
					39 01 00 00 00 00 03 FF 3C 0E
					39 01 00 00 00 00 07 B0 33 00 60 09 38 04
					39 01 00 00 00 00 11 B1 55 00 00 00 44 00 44 40 04 40 04 40 04 19 00 00
					39 01 00 00 00 00 11 B2 41 34 00 f3 37 00 44 30 3f 40 04 40 04 19 00 00
					39 01 00 00 00 00 11 B3 49 00 99 00 48 17 5f 80 04 70 91 80 04 19 00 00
					39 01 00 00 00 00 11 B4 4d 34 99 ef 37 17 5f f0 3e 70 91 80 04 19 00 00
					39 01 00 00 00 00 11 B5 03 12 00 f4 44 0f 55 c0 21 d0 02 e0 01 00 00 00
					39 01 00 00 00 00 11 B6 10 22 00 99 ab 00 12 b0 2a 20 01 20 01 00 00 00
					39 01 00 00 00 00 11 B7 4a 11 00 9d dc 12 52 c0 1d 20 01 e0 03 0a 00 00
					39 01 00 00 00 00 11 B8 42 22 00 5c 9a 12 52 c0 25 20 01 e0 03 0a 00 00
					39 01 00 00 00 00 11 B9 84 12 00 c8 1b 00 14 70 1c 50 01 60 01 01 00 00
					39 01 00 00 00 00 11 BA 88 22 00 1c 6f 00 14 f0 26 40 01 50 01 01 00 00
					39 01 00 00 00 00 39 BB 03 03 00 45 f2 00 00 01 10 10 10 00 00 00 05 00 09 00 00 45 16 01 10 10 10 00 00 00 07 44 09 37 37 45 16 01 10 10 10 00 00 00 01 03 99 49 ee 5f 5f 01 10 10 10 00 00 00
					39 01 00 00 00 00 39 BC 02 12 00 dd 5b 51 51 01 20 20 20 20 20 20 12 00 11 be d2 36 36 aa 20 20 20 20 20 20 02 00 11 be d2 40 40 ff 20 20 00 00 00 00 12 00 11 be d2 4a 4a ff 20 20 20 20 00 00
					39 01 00 00 00 00 39 BD 00 04 aa a3 0c 4f 4f 01 10 10 10 00 00 00 16 44 09 af af b5 a2 01 10 10 10 00 00 00 02 00 11 be d2 68 68 ed 10 10 20 20 10 10 06 11 00 f4 f4 be d2 ff 80 10 00 00 00 00
					39 01 00 00 00 00 39 BE 02 04 00 00 f0 00 00 01 80 00 80 00 80 00 00 04 55 00 f0 ff ff 01 80 00 80 00 80 00 04 55 05 03 03 13 ec 01 40 00 80 00 80 00 06 22 00 1c 1c be d2 eb 0c 20 80 10 0e 0d
					39 01 00 00 00 00 39 BF 16 22 00 26 26 be d2 9c 13 40 25 0f 63 21 06 22 00 30 30 be d2 ff 21 10 42 10 63 10 02 00 00 64 64 f9 f9 ff 20 20 20 20 20 20 12 00 00 6e 6e f9 f9 ff 20 20 20 20 20 20
					39 01 00 00 00 00 39 C0 12 11 00 2c 2c f7 f7 ff 40 10 40 20 40 10 02 11 00 36 36 f7 f7 ff 14 20 14 10 14 20 16 33 00 1b 1b c8 c8 ff 20 20 20 20 20 20 14 33 00 1b 1b d2 d2 ff 20 20 20 20 20 20
					39 01 00 00 00 00 41 C1 00 01 02 03 04 06 07 08 09 0a 0c 0d 0e 0f 10 12 13 14 15 16 18 19 1a 1b 1c 1e 1f 20 21 22 24 25 26 27 28 2a 2b 2c 2d 2e 30 31 32 33 34 36 37 38 39 3a 3c 3d 3e 3f 40 42 43 44 45 46 48 49 4a 4b
					39 01 00 00 00 00 41 C2 00 00 00 00 00 00 00 00 00 00 00 00 00 00 00 00 00 00 00 00 00 00 00 00 00 00 00 00 00 00 00 00 00 00 00 00 00 00 00 00 00 00 00 00 00 00 00 00 00 00 00 00 00 00 00 00 00 00 00 00 00 00 00 00
					39 01 00 00 00 00 41 C3 00 02 05 08 0b 0e 10 13 16 19 1c 1e 21 24 27 2a 2c 2f 32 35 38 3a 3d 40 43 46 48 4b 4e 51 54 56 59 5c 5f 62 64 67 6a 6d 70 72 75 78 7b 7d 80 83 86 89 8c 8e 91 94 97 9a 9c 9f a2 a5 a8 aa ad b0
					39 01 00 00 00 00 41 C4 00 03 07 0a 0e 12 15 19 1c 20 24 27 2b 2e 32 36 39 3d 40 44 48 4b 4f 52 56 5a 5d 61 64 68 6c 6f 73 76 7a 7e 81 85 88 8c 90 93 97 9a 9e a2 a5 a9 ac b0 b4 b7 bb be c2 c6 c9 cd d0 d4 d8 db df e2
					39 01 00 00 00 00 41 C5 00 04 08 0c 10 14 18 1c 20 24 28 2c 30 34 38 3c 40 44 48 4c 50 54 58 5c 60 64 68 6c 70 74 78 7c 80 84 88 8c 90 94 98 9c a0 a4 a8 ac b0 b4 b8 bc c0 c4 c8 cc d0 d4 d8 dc e0 e4 e8 ec f0 f4 f8 fc
					39 01 00 00 00 00 41 C6 00 00 00 00 00 00 01 01 02 03 04 05 06 07 09 0a 0c 0d 0f 11 13 16 18 1b 1d 20 23 26 29 2d 30 34 37 3b 3f 44 48 4d 51 56 5b 60 65 6b 70 76 7c 82 88 8e 95 9c a2 a9 b0 b8 bf c7 cf d7 df e7 ef f8
					39 01 00 00 00 00 41 C7 00 26 34 3f 48 50 57 5d 63 68 6d 72 77 7b 80 84 88 8b 8f 93 96 99 9d a0 a3 a6 a9 ac af b2 b5 b7 ba bd bf c2 c4 c7 c9 cb ce d0 d2 d5 d7 d9 db de e0 e2 e4 e6 e8 ea ec ee f0 f2 f4 f6 f8 f9 fb fd
					39 01 00 00 00 00 41 C8 00 12 1d 25 2d 33 3a 40 45 4b 50 55 59 5e 62 67 6b 6f 73 77 7b 7f 83 86 8a 8e 91 95 98 9b 9f a2 a5 a8 ac af b2 b5 b8 bb be c1 c4 c7 ca cd cf d2 d5 d8 db dd e0 e3 e5 e8 eb ed f0 f2 f5 f8 fa fd
					39 01 00 00 00 00 51 C9 00 00 00 00 00 00 50 55 55 55 55 55 55 aa aa aa 00 0a 14 1e 28 32 3c 46 50 5a 64 6e 78 82 8c 96 a0 aa b4 be c8 d2 dc e6 f0 fa 04 0e 18 22 2c 36 40 4a 54 5e 68 72 7c 86 90 9a a4 ae b8 c2 cc d6 e0 ea f4 fe 08 12 1c 26 30 3a 44 4e 58 62 6c 76
					39 01 00 00 00 00 51 CA aa aa aa fe ff ff ff ff ff ff ff ff ff ff ff ff 80 8a 94 9e a8 b2 bc c6 d0 da e4 ee f8 02 0c 16 20 2a 34 3e 48 52 5c 66 70 7a 84 8e 98 a2 ac b6 c0 ca d4 de e8 f2 fc ff ff ff ff ff ff ff ff ff ff ff ff ff ff ff ff ff ff ff ff ff ff ff ff ff
					39 01 00 00 00 00 79 CB ff 5a 01 00 00 00 00 00 00 00 00 00 00 00 00 00 00 00 00 00 00 00 00 00 ff e8 84 20 bc 58 f4 90 2c c8 64 00 00 00 00 00 00 00 00 00 00 00 00 00 00 00 00 00 00 00 00 00 00 00 00 00 00 00 00 00 00 00 00 00 00 00 00 00 00 00 00 00 00 00 00 00 00 00 00 00 00 00 00 00 00 00 00 00 00 00 00 00 00 00 00 00 00 00 00 00 00 00 00 00 00 00 00 00 00 00 00 00 00 00 00 00
					39 01 00 00 00 00 29 CC 00 00 00 00 00 00 00 00 00 02 04 06 08 0a 0c 0e 10 12 14 16 18 1a 1c 1e 20 22 24 26 28 2a 2c 2e 30 32 34 36 38 3a 3c 3e
					39 01 00 00 00 00 19 CD 00 00 00 00 00 00 00 00 00 00 00 00 00 00 00 00 00 00 00 00 00 00 00 00
					39 01 00 00 00 00 03 FF 3C 0F
					39 01 00 00 00 00 4B B0 00 01 00 72 00 F0 01 A4 02 BC 03 A2 04 38 05 14 06 40 07 FF 0C 1C 0F FF 07 FF 0F FF 03 FF 07 FF 0F FF 00 00 00 00 00 00 00 00 00 00 00 00 00 00 00 00 00 00 00 00 00 00 00 00 00 00 00 00 00 00 00 00 00 00 00 00 00 00 03 FF
					39 01 00 00 00 00 30 B1 00 00 01 00 72 00 F0 01 A4 02 BC 03 A2 04 38 05 14 06 40 0F FF 0F FF 07 FF 0F FF 03 FF 07 FF 0F FF 0F FF 0F FF 0F FF 0F FF 0F FF 00 00 00 00
					39 01 00 00 00 00 65 B2 00 00 0E 10 0E 10 0E 10 0E 10 0E 10 0E 10 0E 10 0E 10 0E 10 0E 10 0E 10 0E 10 00 00 09 C4 09 C4 09 C4 09 C4 09 C4 09 C4 09 C4 09 C4 09 C4 09 C4 09 C4 09 C4 00 00 09 C4 09 C4 09 C4 09 C4 09 C4 09 C4 09 C4 09 C4 09 C4 09 C5 09 C4 09 C4 00 00 09 C4 09 C4 09 C4 09 C4 09 C4 09 C4 09 C4 09 C4 09 C4 09 C4
					39 01 00 00 00 00 27 B3 00 00 00 00 00 00 00 00 08 08 08 08 08 08 08 08 08 08 08 08 08 08 08 08 08 08 08 08 08 08 08 08 08 08 08 08 00 C0
					39 01 00 00 00 00 14 B4 01 02 07 01 5A 50 46 99 03 33 03 CC 02 33 00 66 00 99 00
					39 01 00 00 00 00 2E B5 0B 03 04 46 00 64 00 32 00 04 04 10 80 24 24 4C 2B 00 00 35 01 4C 00 00 00 00 00 24 24 00 00 00 00 06 00 00 00 24 02 00 55 55 00 00 00
					39 01 00 00 00 00 24 B6 00 01 01 23 45 67 01 23 45 67 05 04 03 02 01 00 00 00 00 00 00 00 00 00 00 00 00 00 00 00 00 00 00 00 00
					39 01 00 00 00 00 03 FF 3C 10
					39 01 00 00 00 00 09 B0 15 60 09 38 04 0e 01 00
					39 01 00 00 00 00 4C B1 00 00 00 00 00 00 00 03 01 00 00 03 41 17 00 00 01 17 09 00 00 00 00 00 00 00 00 00 00 00 00 00 03 01 00 00 03 41 17 00 00 01 17 09 00 00 00 00 00 00 00 00 00 00 00 00 09 17 01 00 00 17 41 03 00 00 01 03 00 00 00 00 00 00 00
					39 01 00 00 00 00 4C B2 00 00 00 00 00 00 09 17 01 00 00 17 41 03 00 00 01 03 00 00 00 00 00 00 00 00 00 00 00 00 00 00 03 01 00 00 03 41 17 00 00 01 17 09 00 00 00 00 00 00 00 00 00 00 00 00 00 03 01 00 00 03 41 17 00 00 01 17 09 00 00 00 00 00 00
					39 01 00 00 00 00 4C B3 00 00 00 00 00 00 09 17 01 00 00 17 41 03 00 00 01 03 00 00 00 00 00 00 00 00 00 00 00 00 00 00 03 01 00 00 03 41 17 00 00 01 17 09 00 00 00 00 00 00 00 00 00 00 00 00 00 03 01 00 00 03 41 17 00 00 01 17 09 00 00 00 00 00 00
					39 01 00 00 00 00 4C B4 00 00 00 00 00 00 00 03 01 00 00 03 41 17 00 00 01 17 09 00 00 00 00 00 00 00 00 00 00 00 00 00 03 01 00 00 03 41 17 00 00 01 17 09 00 00 00 00 00 00 00 00 00 00 00 00 09 17 01 00 00 17 41 03 00 00 01 03 00 00 00 00 00 00 00
					39 01 00 00 00 00 03 FF 3C 11
					39 01 00 00 00 00 4F B1 FF FF FF FF FF FF FF FF FF FB FF FF F9 FF FF F3 FF FC F0 FF FA EC FF F9 E7 FF F5 DA FF EF CB FF E9 B7 FF DE 9D FF CA 6F FF FF FF FF FF FF FF FF FF FF FF FF FF FF FF FF FF FF FF FF FF FF FF FF FF FF FF FF FF FF FF FF FF FF FF FF FF 00
					39 01 00 00 00 00 03 FF 3C 0B
					39 01 00 00 00 00 05 B3 01 01 00 B0
					39 01 00 00 05 00 02 70 01
					39 01 00 00 00 00 02 03 11
					39 01 00 00 00 00 05 2A 00 00 04 37
					39 01 00 00 00 00 05 2B 00 00 09 5F
					39 01 00 00 00 00 03 44 05 FF
					39 01 00 00 00 00 02 35 00
					39 01 00 00 00 00 03 4A FF 03
					39 01 00 00 00 00 03 4C FF 03
					39 01 00 00 00 00 03 51 FF 07
					39 01 00 00 00 00 02 53 21
					39 01 00 00 00 00 02 7B 01
					05 01 00 00 0A 00 02 11 00
					05 01 00 00 19 00 02 29 00
				];
				qcom,mdss-dsi-off-command = [
					05 01 00 00 34 00 02 10 00
					05 01 00 00 14 00 02 28 00
				];
				qcom,mdss-dsi-on-command-state = "dsi_lp_mode";
				qcom,mdss-dsi-off-command-state = "dsi_hs_mode";
				qcom,mdss-dsi-h-sync-pulse = <0>;
				qcom,compression-mode = "dsc";
				qcom,mdss-dsc-slice-height = <20>;
				qcom,mdss-dsc-slice-width = <540>;
				qcom,mdss-dsc-slice-per-pkt = <2>;
				qcom,mdss-dsc-bit-per-component = <8>;
				qcom,mdss-dsc-bit-per-pixel = <8>;
				qcom,mdss-dsc-block-prediction-enable;
			};

			timing@2 {
				qcom,mdss-dsi-panel-framerate = <120>;
				qcom,mdss-dsi-panel-width = <1080>;
				qcom,mdss-dsi-panel-height = <2400>;
				qcom,mdss-dsi-h-front-porch = <16>;
				qcom,mdss-dsi-h-back-porch = <8>;
				qcom,mdss-dsi-h-pulse-width = <8>;
				qcom,mdss-dsi-h-sync-skew = <0>;
				qcom,mdss-dsi-v-back-porch = <8>;
				qcom,mdss-dsi-v-front-porch = <28>;
				qcom,mdss-dsi-v-pulse-width = <8>;
				qcom,mdss-dsi-h-left-border = <0>;
				qcom,mdss-dsi-h-right-border = <0>;
				qcom,mdss-dsi-v-top-border = <0>;
				qcom,mdss-dsi-v-bottom-border = <0>;
				//qcom,mdss-dsi-panel-jitter = <0x4 0x1>;
				qcom,mdss-dsi-timing-switch-command = [39 01 00 00 05 00 02 70 02];
				qcom,mdss-dsi-timing-switch-command-state = "dsi_lp_mode";
				qcom,mdss-dsi-on-command = [
					39 01 00 00 00 00 03 F0 3C 3C
					39 01 00 00 00 00 03 F1 3C 3C
					39 01 00 00 00 00 03 FF 3C 00
					39 01 00 00 00 00 05 D0 00 00 00 00
					39 01 00 00 00 00 04 B4 00 00 00
					39 01 00 00 00 00 09 B5 00 40 0A 00 00 C0 0A 00
					39 01 00 00 00 00 03 B7 21 76
					39 01 00 00 00 00 10 C1 02 0C 10 10 44 20 00 00 00 00 00 08 00 00 85
					39 01 00 00 00 00 03 FF 3C 01
					39 01 00 00 00 00 06 B0 50 10 10 15 00
					39 01 00 00 00 00 3B B1 C4 60 09 38 04 D0 02 00 00 00 01 03 00 10 09 60 00 12 00 12 00 10 03 0C 00 12 00 12 00 10 00 10 00 10 00 10 00 10 09 60 00 12 00 12 00 10 00 00 37 04 00 00 5F 09 00 00 FF 00
					39 01 00 00 00 00 17 B2 14 14 03 04 03 04 03 04 07 13 14 14 03 04 03 04 03 04 13 14 14 03
					39 01 00 00 00 00 1B B3 40 01 38 A5 C9 00 30 01 C0 A6 41 00 01 00 00 00 00 11 20 44 35 77 86 AA 9B FF
					39 01 00 00 00 00 06 B4 32 22 26 56 12
					39 01 00 00 00 00 13 B5 00 00 00 00 00 00 04 F0 20 00 00 00 00 00 00 00 00 00
					39 01 00 00 00 00 31 B7 00 FB FC 00 00 00 00 00 00 00 00 00 00 00 00 00 00 00 00 00 00 00 00 00 00 00 00 00 00 00 00 00 00 00 00 00 00 00 00 00 00 00 00 00 00 00 00 00
					39 01 00 00 00 00 0A B8 09 AA 55 AA 55 AA 55 AA 55
					39 01 00 00 00 00 29 BA 24 00 27 00 26 00 0C 00 0B 00 01 00 37 37 37 37 24 00 27 00 26 00 0C 00 0B 00 01 00 37 37 37 37 00 00 00 00 00 00 00 00
					39 01 00 00 00 00 19 BB 00 02 00 00 00 2B 00 00 00 00 79 79 00 00 79 79 00 00 79 79 00 00 79 79
					39 01 00 00 00 00 1B BC 83 01 00 07 00 09 00 0A 00 0C 00 0D 00 0F 00 E6 00 00 E6 00 00 E6 00 00 E6 00
					39 01 00 00 00 00 13 BE 03 00 00 0E 04 00 12 12 00 12 12 00 12 12 00 12 12 00
					39 01 00 00 00 00 12 C0 11 01 00 10 10 64 14 10 64 14 10 64 14 10 64 14 FF
					39 01 00 00 00 00 12 C5 21 02 00 31 00 12 AA 00 12 AA 00 12 AA 00 12 AA FF
					39 01 00 00 00 00 11 C7 66 00 66 00 66 00 00 00 00 66 00 11 00 00 00 00
					39 01 00 00 00 00 32 C8 00 00 00 00 00 00 00 00 06 06 06 00 60 10 00 00 00 00 06 20 00 00 00 00 00 00 00 00 00 00 00 00 00 00 00 00 00 00 00 00 00 00 00 00 00 00 00 00 FF
					39 01 00 00 00 00 63 C9 00 00 25 21 36 00 00 00 56 11 00 00 00 00 00 00 00 00 00 00 00 00 00 00 25 31 26 00 00 00 56 11 00 00 00 00 00 00 00 00 00 00 00 00 00 00 35 12 36 56 12 00 00 00 00 00 00 00 00 00 00 00 00 00 00 00 00 00 00 00 00 35 22 26 00 00 00 56 12 00 00 00 00 00 00 00 00 00 00 00 00 00 00 35 21 26 56 11
					39 01 00 00 00 00 17 CE 01 30 03 03 03 03 03 03 03 03 00 00 02 02 02 00 00 00 00 00 00 FF
					39 01 00 00 00 00 03 FF 3C 02
					39 01 00 00 00 00 1F B0 19 88 08 70 00 54 1E 1E 19 1E 41 10 1E 00 38 77 6C 6C 33 33 33 33 73 33 33 33 32 04 F0 33
					39 01 00 00 00 00 1F B1 09 88 08 6E 00 54 1E 1E 19 1E 41 10 1E 00 38 77 6C 6C 33 33 33 33 73 33 33 33 32 04 F0 33
					39 01 00 00 00 00 2C B2 00 00 77 19 21 29 01 03 05 07 07 08 09 0A 0D 0F 21 25 25 1C 00 77 19 21 29 01 03 05 07 08 09 0A 0B 0D 0F 25 21 21 00 00 00 00 FF
					39 01 00 00 00 00 29 B3 00 00 00 00 01 01 02 03 03 07 04 04 05 06 07 07 08 08 09 09 09 09 09 8B 8C 09 0A 09 0B 0C 0C 0C 00 0E 18 1C 00 00 21 00
					39 01 00 00 00 00 29 B3 00 00 00 00 01 01 02 03 03 07 04 04 05 06 07 07 08 08 09 09 09 09 09 8B 8C 09 0A 09 0B 0C 0C 0C 00 0E 14 18 00 00 21 00
					39 01 00 00 00 00 17 B4 BB BB B0 AA 9A 88 88 78 77 77 77 77 77 77 77 88 08 EC 44 00 21 00
					39 01 00 00 00 00 17 B5 22 22 20 11 11 11 11 00 00 00 00 00 00 00 00 00 00 02 00 00 00 FF
					39 01 00 00 00 00 20 BA 0F 0F 0F 0F 0F 0F 0F 0F 0F 0F 0F 0F 14 15 16 17 18 19 19 19 19 19 19 19 0F 0F 0F 19 19 19 00
					39 01 00 00 00 00 03 FF 3C 03
					39 01 00 00 00 00 A7 B0 00 00 FF 05 00 00 00 00 00 00 98 03 E8 03 1D 04 9A 03 E8 03 1F 04 9F 03 E9 03 24 04 A4 03 EA 03 29 04 A9 03 EB 03 2E 04 AE 03 EC 03 33 04 B3 03 ED 03 38 04 B8 03 EE 03 3D 04 BD 03 EF 03 42 04 C2 03 F0 03 47 04 C7 03 F1 03 4C 04 D2 03 F4 03 56 04 DD 03 F7 03 60 04 E8 03 FA 03 6A 04 FF 03 00 04 7F 04 16 04 06 04 94 04 2D 04 0C 04 A9 04 44 04 12 04 BE 04 44 04 12 04 BE 04 56 04 18 04 CB 04 5F 04 18 04 D2 04 5F 04 18 04 D2 04 91 04 3E 04 08 05 91 04 3E 04 08 05 91 04 3E 04 08 05 91 04 3E 04 08 05
					39 01 00 00 00 00 A7 B1 00 00 FF 05 00 00 00 00 00 00 44 03 36 03 B4 03 0C 04 FE 03 7C 04 70 04 62 04 E0 04 95 04 80 04 18 05 AB 04 94 04 3A 05 C7 04 9F 04 52 05 06 05 D0 04 90 05 10 05 D0 04 98 05 21 05 DB 04 AC 05 37 05 EB 04 C7 05 4B 05 FA 04 DB 05 69 05 0E 05 FB 05 8E 05 2A 05 21 06 AB 05 43 05 42 06 DD 05 6D 05 79 06 11 06 9B 05 B2 06 41 06 C7 05 E6 06 6B 06 EB 05 16 07 98 06 15 06 47 07 BC 06 37 06 71 07 E0 06 58 06 99 07 0C 07 82 06 CE 07 25 07 9B 06 E7 07 3F 07 B2 06 04 08 5C 07 CC 06 27 08 7C 07 EC 06 49 08
					39 01 00 00 00 00 A7 B2 00 00 FF 05 00 00 00 00 00 00 9B 03 84 01 00 00 78 04 67 04 0B 05 78 04 67 04 0B 05 B5 04 88 04 3A 05 D4 04 A2 04 5B 05 F1 04 B6 04 7D 05 39 05 EF 04 C3 05 44 05 F4 04 D2 05 5F 05 07 05 F0 05 7A 05 1C 05 0C 06 92 05 30 05 26 06 B4 05 4A 05 4B 06 DE 05 6E 05 78 06 04 06 8F 05 A2 06 3F 06 C5 05 E4 06 79 06 F9 05 26 07 AF 06 2A 06 63 07 E3 06 5C 06 9D 07 10 07 86 06 D1 07 39 07 AC 06 02 08 60 07 D2 06 2E 08 84 07 F3 06 58 08 AA 07 17 07 83 08 CC 07 36 07 AA 08 EB 07 53 07 CE 08 11 08 70 07 F4 08
					39 01 00 00 00 00 A7 B3 00 00 FF 05 00 00 00 00 00 00 89 03 C5 03 7A 01 EF 03 5F 04 55 02 83 04 6E 04 14 05 D2 04 93 04 54 05 F1 04 B1 04 7F 05 1B 05 D0 04 AB 05 67 05 11 05 F6 05 79 05 1D 05 0B 06 98 05 33 05 2C 06 B2 05 4C 05 48 06 CE 05 62 05 67 06 F7 05 85 05 95 06 24 06 AE 05 C6 06 4D 06 D3 05 F4 06 90 06 0F 06 41 07 D2 06 4C 06 8A 07 0E 07 85 06 CD 07 42 07 B6 06 0B 08 76 07 E5 06 47 08 A4 07 13 07 7C 08 CE 07 38 07 AD 08 F6 07 5E 07 DB 08 20 08 85 07 0C 09 46 08 A8 07 37 09 6A 08 CA 07 62 09 90 08 EA 07 90 09
					39 01 00 00 00 00 A7 B4 00 00 FF 05 00 00 00 00 00 00 E6 03 F1 03 8B 04 4A 04 55 04 EF 04 9C 04 71 04 21 05 E1 04 A6 04 6C 05 17 05 C9 04 A5 05 46 05 ED 04 D6 05 97 05 38 05 2A 06 AC 05 44 05 41 06 D2 05 65 05 6A 06 EE 05 7F 05 89 06 0C 06 99 05 AA 06 3A 06 C2 05 DF 06 6B 06 EF 05 16 07 99 06 19 06 4A 07 E4 06 5E 06 9E 07 29 07 9F 06 EE 07 68 07 DB 06 37 08 9F 07 0D 07 78 08 DD 07 49 07 BD 08 0C 08 73 07 F5 08 3B 08 9E 07 2D 09 6A 08 C7 07 64 09 99 08 F4 07 9B 09 C3 08 1A 08 CD 09 ED 08 3F 08 FF 09 19 09 65 08 32 0A
					39 01 00 00 00 00 A7 B5 00 00 FF 05 00 00 00 00 00 00 F6 03 ED 03 8C 04 5A 04 51 04 F0 04 9E 04 73 04 2B 05 F2 04 B2 04 82 05 2E 05 DA 04 BE 05 61 05 02 05 F2 05 B3 05 4D 05 48 06 C9 05 5E 05 61 06 ED 05 7F 05 88 06 0F 06 9C 05 AE 06 2F 06 B9 05 D0 06 60 06 E6 05 0A 07 95 06 16 06 44 07 C4 06 41 06 7B 07 0E 07 85 06 D2 07 5D 07 D0 06 28 08 9D 07 0D 07 74 08 D8 07 43 07 BA 08 15 08 7C 07 00 09 4B 08 AD 07 40 09 7F 08 DB 07 7D 09 AF 08 09 08 B6 09 E2 08 36 08 F1 09 11 09 5F 08 29 0A 3F 09 87 08 5F 0A 70 09 B2 08 99 0A
					39 01 00 00 00 00 A7 B6 00 00 FF 05 00 00 00 00 00 00 01 00 B8 03 F2 04 5E 04 50 04 F2 04 A6 04 77 04 31 05 FF 04 B8 04 8C 05 3C 05 E3 04 CD 05 71 05 0D 05 03 06 C4 05 5D 05 5B 06 DC 05 71 05 75 06 FF 05 8F 05 9C 06 23 06 AF 05 C3 06 43 06 CC 05 E7 06 76 06 FA 05 22 07 AC 06 2B 06 5F 07 E4 06 5F 06 9D 07 2B 07 A1 06 F1 07 77 07 E8 06 49 08 BA 07 27 07 96 08 F8 07 61 07 DF 08 38 08 9C 07 28 09 70 08 CE 07 6B 09 A5 08 FE 07 A9 09 D8 08 2C 08 E6 09 0E 09 5D 08 25 0A 3F 09 88 08 5F 0A 6F 09 B2 08 98 0A A2 09 DD 08 D4 0A
					39 01 00 00 00 00 A7 B7 00 00 FF 05 00 00 00 00 00 00 33 00 C1 03 EE 04 62 04 54 04 F6 04 B3 04 7E 04 3E 05 10 05 C2 04 9E 05 4F 05 F2 04 E1 05 85 05 1F 05 19 06 DA 05 70 05 73 06 F3 05 84 05 8F 06 1C 06 AA 05 BB 06 40 06 C9 05 E2 06 5F 06 E5 05 06 07 93 06 14 06 43 07 CB 06 48 06 82 07 05 07 7C 06 C2 07 4C 07 BF 06 18 08 A1 07 12 07 77 08 E1 07 4B 07 C3 08 24 08 8A 07 11 09 64 08 C4 07 5D 09 9E 08 F9 07 A1 09 D7 08 2B 08 E5 09 0D 09 5C 08 26 0A 46 09 8E 08 67 0A 7B 09 BC 08 A5 0A AE 09 E7 08 E3 0A E6 09 16 09 23 0B
					39 01 00 00 00 00 A7 B8 00 00 FF 05 00 00 00 00 00 00 44 04 43 04 9C 04 69 04 57 04 FB 04 C0 04 87 04 4B 05 22 05 CF 04 B2 05 63 05 03 05 F4 05 9D 05 33 05 33 06 F3 05 87 05 8E 06 11 06 A0 05 AF 06 38 06 C4 05 DB 06 5E 06 E5 05 04 07 7E 06 01 06 2A 07 B5 06 34 06 69 07 F1 06 6C 06 AB 07 1F 07 97 06 E3 07 76 07 E7 06 48 08 C6 07 32 07 A4 08 11 08 78 07 F9 08 54 08 B4 07 49 09 98 08 F4 07 9A 09 D6 08 2B 08 E3 09 12 09 5F 08 2A 0A 4C 09 93 08 6D 0A 8A 09 C8 08 B5 0A C2 09 F8 08 F9 0A FA 09 27 09 3B 0B 37 0A 5B 09 80 0B
					39 01 00 00 00 00 A7 B9 00 00 FF 05 00 00 00 00 00 00 42 04 38 04 01 05 80 04 57 04 01 05 D8 04 8F 04 5C 05 3B 05 E0 04 CA 05 7E 05 18 05 11 06 BB 05 4E 05 53 06 12 06 A3 05 AF 06 32 06 BC 05 D2 06 5B 06 E1 05 00 07 7F 06 04 06 2B 07 A2 06 24 06 53 07 E0 06 5D 06 98 07 1A 07 91 06 DB 07 4B 07 C1 06 16 08 A7 07 15 07 80 08 FA 07 63 07 E0 08 48 08 AB 07 3B 09 90 08 EC 07 91 09 DA 08 2F 08 E7 09 1C 09 6A 08 35 0A 5E 09 A1 08 83 0A 9D 09 D9 08 CD 0A E1 09 13 09 1C 0B 1F 0A 47 09 66 0B 5E 0A 7D 09 AC 0B A1 0A B5 09 FA 0B
					39 01 00 00 00 00 A7 BA 00 00 FF 05 00 00 00 00 00 00 41 04 2E 04 0E 05 7B 04 64 04 0E 05 FA 04 A7 04 7E 05 62 05 01 05 F4 05 AD 05 42 05 44 06 EE 05 7B 05 8C 06 4A 06 D5 05 EE 06 6C 06 F2 05 15 07 98 06 1A 06 46 07 C1 06 3F 06 74 07 E6 06 63 06 9E 07 26 07 9E 06 E8 07 65 07 DA 06 31 08 9D 07 0D 07 73 08 FE 07 65 07 E5 08 59 08 BA 07 4F 09 B0 08 08 08 B4 09 00 09 4F 08 14 0A 54 09 9B 08 76 0A A1 09 DB 08 D4 0A EE 09 1D 09 2D 0B 3A 0A 5D 09 85 0B 88 0A A0 09 DC 0B D6 0A E0 09 3E 0C 23 0B 20 0A 92 0C 74 0B 66 0A F5 0C
					39 01 00 00 00 00 A7 BB 00 00 FF 05 00 00 00 00 00 00 50 04 45 04 DD 04 86 04 68 04 17 05 1C 05 B7 04 B0 05 80 05 1B 05 14 06 D1 05 62 05 6C 06 13 06 9E 05 B3 06 72 06 FA 05 19 07 95 06 18 06 43 07 C3 06 43 06 76 07 EF 06 6A 06 A8 07 17 07 91 06 D4 07 58 07 CC 06 23 08 99 07 0A 07 6D 08 D7 07 43 07 B4 08 3D 08 A0 07 2D 09 A1 08 FB 07 A3 09 FB 08 4B 08 0D 0A 57 09 9C 08 79 0A B2 09 E9 08 E6 0A 08 0A 33 09 4B 0B 5F 0A 7B 09 AE 0B B5 0A C4 09 12 0C 10 0B 11 0A 7D 0C 69 0B 5B 0A E6 0C C4 0B A8 0A 54 0D 2B 0C FE 0A D7 0D
					39 01 00 00 00 00 A7 C0 00 00 FF 05 00 00 00 00 00 00 F2 03 03 04 8D 04 F3 03 03 04 8D 04 F5 03 04 04 8E 04 F7 03 05 04 8F 04 F9 03 06 04 90 04 FB 03 07 04 91 04 FD 03 08 04 92 04 FF 03 09 04 93 04 01 04 0A 04 94 04 03 04 0B 04 95 04 05 04 0C 04 96 04 0A 04 0E 04 99 04 0F 04 10 04 9C 04 14 04 12 04 9F 04 1E 04 16 04 A6 04 28 04 1A 04 AD 04 32 04 1E 04 B4 04 3C 04 22 04 BB 04 46 04 26 04 C2 04 50 04 2A 04 C9 04 5A 04 2A 04 D2 04 69 04 2C 04 DF 04 69 04 2C 04 DF 04 87 04 3C 04 FB 04 87 04 3C 04 FB 04 87 04 3C 04 FB 04
					39 01 00 00 00 00 A7 C1 00 00 FF 05 00 00 00 00 00 00 42 03 01 00 25 01 42 03 01 00 25 01 42 03 01 00 5C 05 CF 04 BE 04 5C 05 CF 04 BE 04 5C 05 E4 04 C9 04 72 05 10 05 F2 04 9D 05 20 05 F2 04 AC 05 33 05 FC 04 BF 05 45 05 07 05 D5 05 56 05 12 05 E7 05 72 05 21 05 03 06 92 05 3A 05 26 06 B3 05 53 05 4A 06 E3 05 78 05 7E 06 13 06 A2 05 B3 06 41 06 CA 05 E6 06 6B 06 EF 05 16 07 97 06 18 06 46 07 BC 06 39 06 70 07 DF 06 59 06 97 07 0A 07 82 06 CC 07 23 07 9B 06 E5 07 3E 07 B4 06 05 08 5C 07 CD 06 23 08 79 07 EA 06 47 08
					39 01 00 00 00 00 A7 C2 00 00 FF 05 00 00 00 00 00 00 45 04 35 04 C4 04 A2 04 93 04 2F 05 A2 04 93 04 2F 05 D3 04 B2 04 64 05 E9 04 C7 04 75 05 05 05 D6 04 94 05 4A 05 0D 05 D7 05 52 05 0E 05 DF 05 69 05 1D 05 FC 05 82 05 30 05 14 06 99 05 40 05 2E 06 BA 05 58 05 52 06 E4 05 7A 05 7F 06 06 06 98 05 A5 06 3F 06 C9 05 E5 06 79 06 FC 05 27 07 AE 06 2B 06 62 07 E3 06 5D 06 9C 07 0F 07 87 06 D1 07 39 07 AD 06 01 08 60 07 D3 06 2D 08 89 07 F9 06 5B 08 A9 07 18 07 83 08 CA 07 35 07 A8 08 E9 07 52 07 CD 08 10 08 77 07 F6 08
					39 01 00 00 00 00 A7 C3 00 00 FF 05 00 00 00 00 00 00 00 00 2E 04 D7 04 00 00 99 04 D7 04 AA 04 99 04 39 05 DF 04 BC 04 6C 05 06 05 D3 04 94 05 29 05 E8 04 B9 05 73 05 28 05 03 06 80 05 2E 05 12 06 9E 05 42 05 33 06 B9 05 58 05 51 06 D5 05 6F 05 6E 06 FA 05 8E 05 97 06 26 06 B4 05 C8 06 4F 06 D8 05 F6 06 90 06 10 06 40 07 D1 06 4D 06 8B 07 0D 07 84 06 CB 07 3F 07 B3 06 08 08 78 07 E9 06 47 08 A6 07 14 07 7C 08 CC 07 37 07 AA 08 F4 07 5B 07 D9 08 1E 08 82 07 09 09 43 08 A5 07 35 09 67 08 C5 07 60 09 8F 08 EB 07 8F 09
					39 01 00 00 00 00 A7 C5 00 00 FF 05 00 00 00 00 00 00 9A 04 00 00 0E 05 B8 04 00 00 43 05 B8 04 99 04 43 05 FF 04 C7 04 86 05 25 05 E5 04 B5 05 52 05 04 05 E4 05 9E 05 49 05 32 06 B1 05 53 05 47 06 D1 05 6D 05 6A 06 F0 05 87 05 8C 06 0E 06 A0 05 AC 06 3B 06 C6 05 DF 06 6C 06 F4 05 15 07 99 06 1B 06 49 07 E0 06 5C 06 9A 07 26 07 9E 06 EB 07 66 07 D9 06 33 08 9D 07 0C 07 75 08 DB 07 48 07 BA 08 0A 08 71 07 F2 08 39 08 9C 07 29 09 67 08 C5 07 5F 09 96 08 F1 07 96 09 C1 08 18 08 C9 09 EA 08 3D 08 FA 09 16 09 64 08 30 0A
					39 01 00 00 00 00 A7 C6 00 00 FF 05 00 00 00 00 00 00 A4 04 12 00 0B 05 BD 04 2B 00 24 05 C8 04 99 04 4B 05 05 05 CE 04 94 05 38 05 F0 04 C9 05 67 05 13 05 F9 05 B7 05 5B 05 4E 06 D3 05 6E 05 6C 06 F0 05 87 05 8C 06 14 06 A8 05 B3 06 30 06 BE 05 D2 06 60 06 E9 05 09 07 94 06 18 06 43 07 C4 06 43 06 7A 07 11 07 8A 06 D1 07 5B 07 D0 06 26 08 9B 07 0C 07 71 08 D6 07 43 07 B7 08 16 08 7F 07 FF 08 4C 08 AF 07 3C 09 7C 08 DA 07 78 09 AD 08 05 08 B3 09 E0 08 35 08 EE 09 0F 09 5E 08 25 0A 3B 09 85 08 57 0A 6E 09 AF 08 95 0A
					39 01 00 00 00 00 A7 C7 00 00 FF 05 00 00 00 00 00 00 34 04 15 04 CC 04 98 04 79 04 30 05 C2 04 9E 04 4F 05 0F 05 D6 04 9F 05 48 05 FC 04 DA 05 77 05 1F 05 0A 06 C9 05 69 05 5F 06 E0 05 7A 05 7A 06 04 06 99 05 A2 06 27 06 B7 05 C8 06 47 06 D4 05 EB 06 78 06 FE 05 23 07 AC 06 2D 06 5F 07 E4 06 60 06 9D 07 2C 07 A2 06 F2 07 76 07 E8 06 47 08 B8 07 26 07 94 08 F6 07 61 07 DD 08 37 08 9B 07 27 09 6D 08 CD 07 68 09 A2 08 FC 07 A6 09 D6 08 2B 08 E2 09 0B 09 5A 08 21 0A 3D 09 86 08 5C 0A 6D 09 B0 08 94 0A A0 09 DB 08 D4 0A
					39 01 00 00 00 00 A7 C8 00 00 FF 05 00 00 00 00 00 00 46 04 5A 04 1F 05 9E 04 7A 04 34 05 CC 04 A3 04 57 05 1C 05 DE 04 AD 05 57 05 07 05 E7 05 8A 05 2E 05 1F 06 DF 05 7C 05 77 06 F5 05 8C 05 91 06 1A 06 AC 05 BA 06 3D 06 CB 05 E1 06 5F 06 E8 05 06 07 96 06 1A 06 45 07 C8 06 47 06 7F 07 01 07 7A 06 BF 07 49 07 BD 06 15 08 9A 07 0B 07 71 08 E0 07 4B 07 C1 08 20 08 86 07 0D 09 62 08 C3 07 5B 09 9C 08 F8 07 9F 09 D2 08 27 08 DE 09 0A 09 59 08 22 0A 44 09 8C 08 64 0A 78 09 B9 08 A1 0A AC 09 E6 08 DE 0A E2 09 13 09 1F 0B
					39 01 00 00 00 00 A7 C9 00 00 FF 05 00 00 00 00 00 00 94 04 24 04 C1 04 94 04 86 04 24 05 D6 04 AA 04 63 05 2D 05 E8 04 BE 05 6C 05 16 05 FE 05 A1 05 3F 05 38 06 F6 05 8F 05 90 06 10 06 A4 05 AF 06 37 06 C7 05 DA 06 5E 06 E8 05 04 07 7E 06 04 06 29 07 B4 06 35 06 67 07 ED 06 69 06 A8 07 1E 07 98 06 E1 07 74 07 E6 06 45 08 C4 07 31 07 A2 08 0D 08 75 07 F6 08 51 08 B2 07 46 09 95 08 F1 07 96 09 D3 08 29 08 E0 09 0F 09 5C 08 27 0A 49 09 90 08 6A 0A 86 09 C5 08 B1 0A BF 09 F7 08 F5 0A F7 09 24 09 37 0B 30 0A 57 09 7A 0B
					39 01 00 00 00 00 A7 CA 00 00 FF 05 00 00 00 00 00 00 4A 04 3B 04 2A 05 97 04 89 04 2A 05 E4 04 B2 04 72 05 43 05 F8 04 D5 05 85 05 29 05 1A 06 BC 05 56 05 56 06 13 06 AA 05 B0 06 33 06 C1 05 D5 06 59 06 E3 05 FF 06 80 06 07 06 2C 07 A2 06 26 06 52 07 DD 06 5C 06 95 07 17 07 90 06 D8 07 4C 07 C3 06 16 08 A5 07 16 07 7C 08 F7 07 61 07 DD 08 45 08 A8 07 37 09 8D 08 E9 07 8D 09 D7 08 2C 08 E4 09 19 09 66 08 31 0A 5A 09 9F 08 7E 0A 9A 09 D6 08 C9 0A DE 09 10 09 18 0B 1C 0A 44 09 63 0B 5A 0A 79 09 AB 0B 9D 0A B2 09 F8 0B
					39 01 00 00 00 00 A7 CB 00 00 FF 05 00 00 00 00 00 00 7B 04 6F 04 24 05 A2 04 8F 04 32 05 07 05 C3 04 8F 05 6A 05 14 05 FB 05 B4 05 50 05 4D 06 F0 05 83 05 8E 06 4D 06 DB 05 EF 06 6D 06 F6 05 14 07 98 06 1D 06 45 07 C1 06 42 06 75 07 E7 06 64 06 9F 07 24 07 9D 06 E7 07 63 07 D8 06 2F 08 9B 07 0B 07 71 08 FC 07 63 07 E2 08 57 08 B8 07 4D 09 AD 08 06 08 B2 09 FC 08 4C 08 11 0A 51 09 97 08 73 0A 9F 09 DA 08 CE 0A EB 09 1A 09 2A 0B 37 0A 5A 09 82 0B 86 0A 9E 09 DE 0B D3 0A DD 09 37 0C 20 0B 1D 0A 8F 0C 71 0B 61 0A F8 0C
					39 01 00 00 00 00 A7 CC 00 00 FF 05 00 00 00 00 00 00 B2 04 6F 02 1E 00 B3 04 93 04 22 05 0E 05 D2 04 A5 05 87 05 2A 05 1B 06 D4 05 6C 05 6F 06 14 06 A3 05 B7 06 73 06 FD 05 1A 07 96 06 1C 06 43 07 C3 06 44 06 77 07 EE 06 6D 06 A7 07 17 07 92 06 D5 07 57 07 CD 06 23 08 98 07 0A 07 6D 08 D5 07 41 07 B4 08 3A 08 9D 07 2A 09 9D 08 F8 07 A0 09 F8 08 49 08 0A 0A 53 09 97 08 75 0A AF 09 E8 08 E1 0A 05 0A 30 09 48 0B 5A 0A 78 09 AB 0B B1 0A C0 09 0D 0C 0C 0B 0D 0A 78 0C 65 0B 57 0A E3 0C BF 0B A4 0A 52 0D 29 0C FC 0A D2 0D
					39 01 00 00 00 00 A7 D0 00 00 FF 05 00 00 00 00 00 00 35 04 57 04 9E 04 35 04 57 04 9F 04 36 04 57 04 A1 04 37 04 57 04 A3 04 38 04 57 04 A5 04 39 04 57 04 A7 04 3A 04 57 04 A9 04 3B 04 57 04 AB 04 3C 04 57 04 AD 04 3D 04 57 04 AF 04 3E 04 57 04 B1 04 41 04 57 04 B5 04 44 04 57 04 B9 04 47 04 57 04 BD 04 4E 04 57 04 C5 04 55 04 57 04 CD 04 5C 04 57 04 D5 04 63 04 57 04 DD 04 6A 04 57 04 E5 04 71 04 57 04 ED 04 79 04 57 04 EF 04 85 04 58 04 FB 04 85 04 58 04 FB 04 8F 04 58 04 06 05 91 04 58 04 07 05 9A 04 59 04 0A 05
					39 01 00 00 00 00 A7 D1 00 00 FF 05 00 00 00 00 00 00 A8 04 B0 04 34 05 AF 04 B4 04 3B 05 BE 04 BC 04 4A 05 CD 04 C4 04 59 05 DC 04 CC 04 68 05 EB 04 D4 04 77 05 FC 04 DD 04 89 05 0A 05 E4 04 97 05 1A 05 EC 04 A9 05 2F 05 F8 04 BE 05 3D 05 00 05 CD 05 60 05 17 05 F2 05 7F 05 2E 05 13 06 9D 05 44 05 33 06 D7 05 70 05 73 06 06 06 99 05 A7 06 33 06 BF 05 D9 06 5C 06 E2 05 08 07 84 06 06 06 34 07 A8 06 27 06 5D 07 CB 06 46 06 85 07 EC 06 65 06 AB 07 0A 07 7F 06 CC 07 27 07 9B 06 EE 07 42 07 B5 06 0D 08 58 07 CE 06 2F 08
					39 01 00 00 00 00 A7 D2 00 00 FF 05 00 00 00 00 00 00 9A 04 98 04 2C 05 A7 04 A2 04 38 05 C2 04 B6 04 50 05 DD 04 CA 04 68 05 F1 04 D5 04 7E 05 07 05 DF 04 96 05 21 05 F0 04 B1 05 37 05 FA 04 C6 05 4F 05 09 05 E2 05 64 05 18 05 F7 05 7C 05 29 05 10 06 A6 05 4A 05 3D 06 CC 05 69 05 68 06 F0 05 85 05 8F 06 32 06 BD 05 D8 06 6E 06 F3 05 1B 07 9F 06 1F 06 54 07 D0 06 4C 06 8B 07 FC 06 74 06 BE 07 25 07 9B 06 ED 07 4C 07 BF 06 19 08 6F 07 E0 06 43 08 91 07 FE 06 6A 08 B3 07 1F 07 92 08 D1 07 39 07 B5 08 F1 07 57 07 DB 08
					39 01 00 00 00 00 A7 D3 00 00 FF 05 00 00 00 00 00 00 62 04 6E 04 C3 04 B3 04 A8 04 2D 05 CA 04 BA 04 58 05 ED 04 CA 04 7E 05 05 05 DE 04 98 05 27 05 EE 04 B7 05 47 05 06 05 D8 05 60 05 14 05 F4 05 7E 05 2A 05 15 06 99 05 3F 05 30 06 B2 05 52 05 4A 06 E3 05 7B 05 81 06 0F 06 A0 05 B1 06 38 06 C3 05 E0 06 81 06 04 06 32 07 C3 06 42 06 7B 07 FC 06 74 06 BD 07 31 07 A6 06 F9 07 61 07 D2 06 32 08 91 07 01 07 6A 08 B7 07 22 07 95 08 E0 07 48 07 C4 08 06 08 6B 07 F2 08 2B 08 8D 07 1D 09 4F 08 AE 07 48 09 75 08 D1 07 72 09
					39 01 00 00 00 00 A7 D4 00 00 FF 05 00 00 00 00 00 00 76 04 4F 04 E6 04 76 04 A9 04 42 05 D1 04 BD 04 5E 05 FA 04 D5 04 88 05 22 05 EB 04 B3 05 49 05 05 05 DA 05 71 05 20 05 04 06 90 05 37 05 26 06 B3 05 51 05 4D 06 D2 05 6C 05 6F 06 EE 05 82 05 8B 06 24 06 B2 05 C8 06 54 06 DD 05 FE 06 82 06 04 06 32 07 D2 06 50 06 8D 07 18 07 8F 06 DC 07 56 07 CA 06 25 08 8F 07 FF 06 67 08 C4 07 2F 07 A4 08 F8 07 62 07 E1 08 25 08 88 07 15 09 52 08 B1 07 4A 09 80 08 DA 07 7F 09 AA 08 00 08 B1 09 D3 08 25 08 E3 09 FE 08 49 08 17 0A
					39 01 00 00 00 00 A7 D5 00 00 FF 05 00 00 00 00 00 00 08 00 46 04 5D 00 6C 00 AA 04 C1 00 D3 04 BB 04 64 05 07 05 D5 04 96 05 34 05 F3 04 C7 05 5F 05 12 05 F1 05 8B 05 32 05 20 06 AD 05 4C 05 45 06 D0 05 6A 05 6D 06 F2 05 87 05 90 06 11 06 A0 05 B2 06 49 06 D3 05 F3 06 7D 06 01 06 2C 07 AD 06 2B 06 63 07 01 07 7A 06 C3 07 49 07 BE 06 18 08 89 07 FA 06 61 08 C8 07 33 07 A9 08 01 08 66 07 EB 08 3A 08 9B 07 2A 09 68 08 C4 07 63 09 99 08 F0 07 9D 09 C9 08 1C 08 D7 09 F7 08 44 08 0D 0A 25 09 6C 08 43 0A 53 09 94 08 7A 0A
					39 01 00 00 00 00 A7 D6 00 00 FF 05 00 00 00 00 00 00 49 04 40 04 D3 04 AD 04 A4 04 37 05 D9 04 BE 04 6A 05 0F 05 DC 04 9F 05 3E 05 FC 04 D0 05 6D 05 1C 05 01 06 99 05 3D 05 30 06 BD 05 5A 05 57 06 E3 05 79 05 80 06 08 06 97 05 A8 06 24 06 B2 05 C8 06 5E 06 E6 05 0B 07 93 06 16 06 46 07 C3 06 43 06 7C 07 1C 07 94 06 E3 07 65 07 D8 06 38 08 A8 07 16 07 85 08 E9 07 54 07 CE 08 23 08 87 07 14 09 59 08 B8 07 53 09 8E 08 E7 07 91 09 C1 08 15 08 CD 09 F3 08 42 08 09 0A 24 09 6C 08 42 0A 53 09 96 08 7F 0A 81 09 BF 08 B7 0A
					39 01 00 00 00 00 A7 D7 00 00 FF 05 00 00 00 00 00 00 AB 04 01 00 2F 05 E0 04 01 00 4F 05 E0 04 C2 04 71 05 1B 05 E5 04 AB 05 4F 05 07 05 E2 05 7F 05 2A 05 14 06 AE 05 4E 05 47 06 D3 05 6C 05 6F 06 FA 05 8D 05 99 06 1D 06 AB 05 C1 06 3D 06 C9 05 E6 06 7B 06 FF 05 2A 07 B1 06 30 06 68 07 EA 06 63 06 A8 07 3C 07 B1 06 09 08 8A 07 FB 06 62 08 CF 07 3A 07 B2 08 11 08 76 07 FE 08 4E 08 AD 07 47 09 88 08 E3 07 8B 09 C0 08 14 08 CD 09 F6 08 44 08 0D 0A 2B 09 73 08 4C 0A 60 09 A0 08 88 0A 94 09 CC 08 C7 0A C6 09 F6 08 07 0B
					39 01 00 00 00 00 A7 D8 00 00 FF 05 00 00 00 00 00 00 AD 04 00 00 41 05 B4 04 A8 04 41 05 EA 04 C7 04 7A 05 2A 05 F0 04 BA 05 61 05 14 05 F5 05 98 05 3D 05 2F 06 C9 05 63 05 63 06 EC 05 82 05 8B 06 15 06 A5 05 B8 06 39 06 C5 05 E0 06 5B 06 E3 05 07 07 9E 06 1F 06 51 07 D7 06 54 06 91 07 09 07 83 06 CA 07 65 07 DA 06 35 08 B4 07 22 07 93 08 FD 07 64 07 E6 08 41 08 A2 07 38 09 82 08 DC 07 84 09 C2 08 16 08 CD 09 FB 08 4A 08 13 0A 35 09 7C 08 57 0A 6E 09 AD 08 9A 0A A7 09 DE 08 DD 0A DF 09 0E 09 1E 0B 18 0A 3C 09 62 0B
					39 01 00 00 00 00 A7 D9 00 00 FF 05 00 00 00 00 00 00 D0 00 CF 00 4F 05 BB 04 AA 04 51 05 FA 04 CE 04 87 05 3D 05 F9 04 D0 05 7C 05 27 05 12 06 B3 05 52 05 4B 06 E6 05 7D 05 84 06 0C 06 9D 05 AE 06 36 06 C4 05 DE 06 60 06 E8 05 0B 07 81 06 04 06 30 07 C5 06 44 06 7D 07 01 07 7B 06 C2 07 35 07 AC 06 FE 07 96 07 06 07 6D 08 E8 07 51 07 CE 08 35 08 98 07 29 09 7E 08 DA 07 80 09 C4 08 17 08 D1 09 06 09 53 08 1E 0A 48 09 8C 08 6B 0A 88 09 C2 08 B7 0A C7 09 F8 08 01 0B 04 0A 2C 09 4B 0B 43 0A 61 09 93 0B 83 0A 96 09 D8 0B
					39 01 00 00 00 00 A7 DE 00 00 FF 05 00 00 00 00 00 00 92 04 9A 04 32 05 C0 04 B0 04 51 05 0F 05 DD 04 9F 05 61 05 15 05 F5 05 A7 05 49 05 3F 06 E3 05 7A 05 80 06 1B 06 AB 05 BF 06 46 06 D0 05 EE 06 76 06 FB 05 24 07 9F 06 20 06 53 07 C3 06 43 06 7D 07 0B 07 84 06 CE 07 4A 07 BF 06 16 08 83 07 F4 06 59 08 EA 07 53 07 D3 08 47 08 A8 07 3D 09 9D 08 F5 07 A3 09 EE 08 3F 08 02 0A 3E 09 84 08 60 0A 8C 09 C5 08 BD 0A D7 09 05 09 16 0B 22 0A 45 09 6D 0B 6E 0A 84 09 C4 0B BA 0A C5 09 1D 0C 08 0B 04 0A 77 0C 54 0B 45 0A D4 0C
					39 01 00 00 00 00 A7 DF 00 00 FF 05 00 00 00 00 00 00 26 03 A1 04 05 05 C8 04 B4 04 58 05 24 05 E9 04 B5 05 7F 05 29 05 14 06 C7 05 62 05 62 06 06 06 99 05 A7 06 41 06 CD 05 EA 06 6F 06 F5 05 1C 07 A2 06 23 06 55 07 CA 06 49 06 85 07 F4 06 6E 06 B2 07 3D 07 B3 06 0A 08 7E 07 F0 06 53 08 BB 07 29 07 9B 08 2A 08 8E 07 1B 09 8E 08 E9 07 92 09 E8 08 38 08 FB 09 44 09 89 08 66 0A 9C 09 D4 08 D1 0A F1 09 1C 09 35 0B 47 0A 65 09 98 0B 9D 0A AD 09 FA 0B F6 0A F6 09 61 0C 4D 0B 3F 0A CA 0C AA 0B 8B 0A 39 0D 0C 0C DF 0A B5 0D
					39 01 00 00 00 00 A7 BD 00 00 FF 05 00 00 00 00 00 00 F9 00 00 00 09 01 E8 03 01 00 37 04 00 04 6F 00 92 04 00 04 6F 02 92 04 0B 04 FE 03 9C 04 2B 04 11 04 BA 04 51 04 28 04 E0 04 7D 04 43 04 10 05 8C 04 4D 04 20 05 8C 04 4D 04 20 05 A4 04 62 04 39 05 D2 04 87 04 6A 05 F0 04 9A 04 8B 05 0F 05 B3 04 AD 05 41 05 E1 04 E1 05 72 05 0C 05 14 06 AA 05 36 05 58 06 D3 05 5B 05 86 06 FC 05 7F 05 B4 06 20 06 A0 05 DE 06 43 06 C0 05 06 07 64 06 DE 05 2B 07 85 06 FD 05 51 07 A2 06 1A 06 72 07 C0 06 38 06 95 07 D9 06 4E 06 B1 07
					39 01 00 00 00 00 A7 BE 00 00 FF 05 00 00 00 00 00 00 F2 01 00 00 12 02 F0 03 01 00 56 04 00 04 9E 01 92 04 0C 04 FF 03 9D 04 3A 04 1A 04 C8 04 72 04 3C 04 04 05 8C 04 4D 04 20 05 95 04 55 04 29 05 C0 04 7C 04 57 05 D5 04 88 04 6E 05 E9 04 95 04 84 05 15 05 B8 04 B4 05 39 05 D8 04 DA 05 53 05 F5 04 EF 05 A3 05 2F 05 4F 06 DB 05 62 05 8F 06 12 06 93 05 CE 06 41 06 BE 05 04 07 6E 06 E7 05 36 07 99 06 11 06 67 07 C1 06 39 06 97 07 E4 06 57 06 BE 07 08 07 79 06 E6 07 2B 07 99 06 0C 08 46 07 B3 06 28 08 58 07 BF 06 4F 08
					39 01 00 00 00 00 A7 BF 00 00 FF 05 00 00 00 00 00 00 E4 03 01 00 25 04 00 04 01 00 92 04 00 04 F8 03 92 04 3C 04 1B 04 C9 04 8C 04 4D 04 20 05 8C 04 4D 04 20 05 C7 04 82 04 5E 05 DF 04 8D 04 79 05 FE 04 A5 04 9A 05 1B 05 BD 04 BA 05 35 05 D3 04 D7 05 59 05 FB 04 F4 05 96 05 24 05 41 06 C0 05 4A 05 70 06 0B 06 8D 05 C6 06 4C 06 C8 05 10 07 89 06 01 06 55 07 C0 06 38 06 95 07 F0 06 62 06 CB 07 23 07 92 06 04 08 48 07 B5 06 2A 08 60 07 C5 06 61 08 97 07 FF 06 8D 08 BD 07 21 07 B8 08 E2 07 43 07 E3 08 04 08 62 07 09 09
					39 01 00 00 00 00 A7 BC 00 00 FF 05 00 00 00 00 00 00 7E 02 8A 02 C6 03 D6 02 CC 02 1E 04 62 03 6D 03 AB 04 08 04 F9 03 64 05 89 04 67 04 EC 05 F3 04 C6 04 5C 06 5F 05 25 05 DD 06 A9 05 64 05 23 07 F2 05 A6 05 70 07 36 06 E1 05 B4 07 76 06 1A 06 F4 07 E3 06 7A 06 5F 08 46 07 D3 06 C0 08 A1 07 24 07 19 09 43 08 B4 07 B9 09 D4 08 33 08 53 0A 59 09 AA 08 E6 0A D7 09 18 09 73 0B 51 0A 83 09 FD 0B C2 0A E4 09 83 0C 34 0B 44 0A 03 0D A4 0B A2 0A 82 0D 17 0C 01 0B 03 0E 83 0C 5E 0B 82 0E F6 0C B9 0B 01 0F 67 0D 17 0C 82 0F
					39 01 00 00 00 00 A7 E4 00 00 FF 05 84 0D D4 0B EA 0F 84 0D D4 0B EA 0F 84 0D D4 0B EA 0F 84 0D D4 0B EA 0F 84 0D D4 0B EA 0F 84 0D D4 0B EA 0F 84 0D D4 0B EA 0F 84 0D D4 0B EA 0F 84 0D D4 0B EA 0F 84 0D D4 0B EA 0F 84 0D D4 0B EA 0F 84 0D D4 0B EA 0F 84 0D D4 0B EA 0F 84 0D D4 0B EA 0F 84 0D D4 0B EA 0F 84 0D D4 0B EA 0F 84 0D D4 0B EA 0F 84 0D D4 0B EA 0F 84 0D D4 0B EA 0F 84 0D D4 0B EA 0F 84 0D D4 0B EA 0F 84 0D D4 0B EA 0F 84 0D D4 0B EA 0F 84 0D D4 0B EA 0F 84 0D D4 0B EA 0F 84 0D D4 0B EA 0F 84 0D D4 0B EA 0F
					39 01 00 00 00 00 03 FF 3C 04
					39 01 00 00 00 00 2C B2 00 0A 77 66 55 44 33 22 11 11 10 00 00 00 00 00 FF 7E FE 7E FD 7D FD 7D FC 7C FC 7C FB BB 7B 3A 1A FA DA BB 99 79 59 38 18 08 FE
					39 01 00 00 00 00 09 B3 0C 02 3C 00 00 00 00 00
					39 01 00 00 00 00 03 FF 3C 05
					39 01 00 00 00 00 17 B1 F0 01 C0 08 22 02 7C 08 DE 60 00 00 00 00 00 00 00 00 00 00 00 00
					39 01 00 00 00 00 81 D0 11 00 00 89 30 80 09 60 04 38 00 14 02 1C 02 1C 02 00 02 0E 00 20 03 2E 00 07 00 0C 03 00 03 15 18 00 10 F0 03 0C 20 00 06 0B 0B 33 0E 1C 2A 38 46 54 62 69 70 77 79 7B 7D 7E 01 02 01 00 09 40 09 BE 19 FC 19 FA 19 F8 1A 38 1A 78 1A B6 2A F6 2B 34 2B 74 3B 74 6B F4 00 00 00 00 00 00 00 00 00 00 00 00 00 00 00 00 00 00 00 00 00 00 00 00 00 00 00 00 00 00 00 00 00 00 00 00 00 00 00 00
					39 01 00 00 00 00 81 D1 11 00 00 89 30 80 09 60 04 38 00 14 02 1C 02 1C 02 00 02 0E 00 20 03 2E 00 07 00 0C 03 00 03 15 18 00 10 F0 03 0C 20 00 06 0B 0B 33 0E 1C 2A 38 46 54 62 69 70 77 79 7B 7D 7E 01 02 01 00 09 40 09 BE 19 FC 19 FA 19 F8 1A 38 1A 78 1A B6 2A F6 2B 34 2B 74 3B 74 6B F4 00 00 00 00 00 00 00 00 00 00 00 00 00 00 00 00 00 00 00 00 00 00 00 00 00 00 00 00 00 00 00 00 00 00 00 00 00 00 00 00
					39 01 00 00 00 00 03 FF 3C 0A
					39 01 00 00 00 00 15 B0 00 00 10 00 00 00 00 00 00 00 00 00 00 00 00 00 00 00 00 00
					39 01 00 00 00 00 03 FF 3C 0E
					39 01 00 00 00 00 07 B0 33 00 60 09 38 04
					39 01 00 00 00 00 11 B1 55 00 00 00 44 00 44 40 04 40 04 40 04 19 00 00
					39 01 00 00 00 00 11 B2 41 34 00 f3 37 00 44 30 3f 40 04 40 04 19 00 00
					39 01 00 00 00 00 11 B3 49 00 99 00 48 17 5f 80 04 70 91 80 04 19 00 00
					39 01 00 00 00 00 11 B4 4d 34 99 ef 37 17 5f f0 3e 70 91 80 04 19 00 00
					39 01 00 00 00 00 11 B5 03 12 00 f4 44 0f 55 c0 21 d0 02 e0 01 00 00 00
					39 01 00 00 00 00 11 B6 10 22 00 99 ab 00 12 b0 2a 20 01 20 01 00 00 00
					39 01 00 00 00 00 11 B7 4a 11 00 9d dc 12 52 c0 1d 20 01 e0 03 0a 00 00
					39 01 00 00 00 00 11 B8 42 22 00 5c 9a 12 52 c0 25 20 01 e0 03 0a 00 00
					39 01 00 00 00 00 11 B9 84 12 00 c8 1b 00 14 70 1c 50 01 60 01 01 00 00
					39 01 00 00 00 00 11 BA 88 22 00 1c 6f 00 14 f0 26 40 01 50 01 01 00 00
					39 01 00 00 00 00 39 BB 03 03 00 45 f2 00 00 01 10 10 10 00 00 00 05 00 09 00 00 45 16 01 10 10 10 00 00 00 07 44 09 37 37 45 16 01 10 10 10 00 00 00 01 03 99 49 ee 5f 5f 01 10 10 10 00 00 00
					39 01 00 00 00 00 39 BC 02 12 00 dd 5b 51 51 01 20 20 20 20 20 20 12 00 11 be d2 36 36 aa 20 20 20 20 20 20 02 00 11 be d2 40 40 ff 20 20 00 00 00 00 12 00 11 be d2 4a 4a ff 20 20 20 20 00 00
					39 01 00 00 00 00 39 BD 00 04 aa a3 0c 4f 4f 01 10 10 10 00 00 00 16 44 09 af af b5 a2 01 10 10 10 00 00 00 02 00 11 be d2 68 68 ed 10 10 20 20 10 10 06 11 00 f4 f4 be d2 ff 80 10 00 00 00 00
					39 01 00 00 00 00 39 BE 02 04 00 00 f0 00 00 01 80 00 80 00 80 00 00 04 55 00 f0 ff ff 01 80 00 80 00 80 00 04 55 05 03 03 13 ec 01 40 00 80 00 80 00 06 22 00 1c 1c be d2 eb 0c 20 80 10 0e 0d
					39 01 00 00 00 00 39 BF 16 22 00 26 26 be d2 9c 13 40 25 0f 63 21 06 22 00 30 30 be d2 ff 21 10 42 10 63 10 02 00 00 64 64 f9 f9 ff 20 20 20 20 20 20 12 00 00 6e 6e f9 f9 ff 20 20 20 20 20 20
					39 01 00 00 00 00 39 C0 12 11 00 2c 2c f7 f7 ff 40 10 40 20 40 10 02 11 00 36 36 f7 f7 ff 14 20 14 10 14 20 16 33 00 1b 1b c8 c8 ff 20 20 20 20 20 20 14 33 00 1b 1b d2 d2 ff 20 20 20 20 20 20
					39 01 00 00 00 00 41 C1 00 01 02 03 04 06 07 08 09 0a 0c 0d 0e 0f 10 12 13 14 15 16 18 19 1a 1b 1c 1e 1f 20 21 22 24 25 26 27 28 2a 2b 2c 2d 2e 30 31 32 33 34 36 37 38 39 3a 3c 3d 3e 3f 40 42 43 44 45 46 48 49 4a 4b
					39 01 00 00 00 00 41 C2 00 00 00 00 00 00 00 00 00 00 00 00 00 00 00 00 00 00 00 00 00 00 00 00 00 00 00 00 00 00 00 00 00 00 00 00 00 00 00 00 00 00 00 00 00 00 00 00 00 00 00 00 00 00 00 00 00 00 00 00 00 00 00 00
					39 01 00 00 00 00 41 C3 00 02 05 08 0b 0e 10 13 16 19 1c 1e 21 24 27 2a 2c 2f 32 35 38 3a 3d 40 43 46 48 4b 4e 51 54 56 59 5c 5f 62 64 67 6a 6d 70 72 75 78 7b 7d 80 83 86 89 8c 8e 91 94 97 9a 9c 9f a2 a5 a8 aa ad b0
					39 01 00 00 00 00 41 C4 00 03 07 0a 0e 12 15 19 1c 20 24 27 2b 2e 32 36 39 3d 40 44 48 4b 4f 52 56 5a 5d 61 64 68 6c 6f 73 76 7a 7e 81 85 88 8c 90 93 97 9a 9e a2 a5 a9 ac b0 b4 b7 bb be c2 c6 c9 cd d0 d4 d8 db df e2
					39 01 00 00 00 00 41 C5 00 04 08 0c 10 14 18 1c 20 24 28 2c 30 34 38 3c 40 44 48 4c 50 54 58 5c 60 64 68 6c 70 74 78 7c 80 84 88 8c 90 94 98 9c a0 a4 a8 ac b0 b4 b8 bc c0 c4 c8 cc d0 d4 d8 dc e0 e4 e8 ec f0 f4 f8 fc
					39 01 00 00 00 00 41 C6 00 00 00 00 00 00 01 01 02 03 04 05 06 07 09 0a 0c 0d 0f 11 13 16 18 1b 1d 20 23 26 29 2d 30 34 37 3b 3f 44 48 4d 51 56 5b 60 65 6b 70 76 7c 82 88 8e 95 9c a2 a9 b0 b8 bf c7 cf d7 df e7 ef f8
					39 01 00 00 00 00 41 C7 00 26 34 3f 48 50 57 5d 63 68 6d 72 77 7b 80 84 88 8b 8f 93 96 99 9d a0 a3 a6 a9 ac af b2 b5 b7 ba bd bf c2 c4 c7 c9 cb ce d0 d2 d5 d7 d9 db de e0 e2 e4 e6 e8 ea ec ee f0 f2 f4 f6 f8 f9 fb fd
					39 01 00 00 00 00 41 C8 00 12 1d 25 2d 33 3a 40 45 4b 50 55 59 5e 62 67 6b 6f 73 77 7b 7f 83 86 8a 8e 91 95 98 9b 9f a2 a5 a8 ac af b2 b5 b8 bb be c1 c4 c7 ca cd cf d2 d5 d8 db dd e0 e3 e5 e8 eb ed f0 f2 f5 f8 fa fd
					39 01 00 00 00 00 51 C9 00 00 00 00 00 00 50 55 55 55 55 55 55 aa aa aa 00 0a 14 1e 28 32 3c 46 50 5a 64 6e 78 82 8c 96 a0 aa b4 be c8 d2 dc e6 f0 fa 04 0e 18 22 2c 36 40 4a 54 5e 68 72 7c 86 90 9a a4 ae b8 c2 cc d6 e0 ea f4 fe 08 12 1c 26 30 3a 44 4e 58 62 6c 76
					39 01 00 00 00 00 51 CA aa aa aa fe ff ff ff ff ff ff ff ff ff ff ff ff 80 8a 94 9e a8 b2 bc c6 d0 da e4 ee f8 02 0c 16 20 2a 34 3e 48 52 5c 66 70 7a 84 8e 98 a2 ac b6 c0 ca d4 de e8 f2 fc ff ff ff ff ff ff ff ff ff ff ff ff ff ff ff ff ff ff ff ff ff ff ff ff ff
					39 01 00 00 00 00 79 CB ff 5a 01 00 00 00 00 00 00 00 00 00 00 00 00 00 00 00 00 00 00 00 00 00 ff e8 84 20 bc 58 f4 90 2c c8 64 00 00 00 00 00 00 00 00 00 00 00 00 00 00 00 00 00 00 00 00 00 00 00 00 00 00 00 00 00 00 00 00 00 00 00 00 00 00 00 00 00 00 00 00 00 00 00 00 00 00 00 00 00 00 00 00 00 00 00 00 00 00 00 00 00 00 00 00 00 00 00 00 00 00 00 00 00 00 00 00 00 00 00 00 00
					39 01 00 00 00 00 29 CC 00 00 00 00 00 00 00 00 00 02 04 06 08 0a 0c 0e 10 12 14 16 18 1a 1c 1e 20 22 24 26 28 2a 2c 2e 30 32 34 36 38 3a 3c 3e
					39 01 00 00 00 00 19 CD 00 00 00 00 00 00 00 00 00 00 00 00 00 00 00 00 00 00 00 00 00 00 00 00
					39 01 00 00 00 00 03 FF 3C 0F
					39 01 00 00 00 00 4B B0 00 01 00 72 00 F0 01 A4 02 BC 03 A2 04 38 05 14 06 40 07 FF 0C 1C 0F FF 07 FF 0F FF 03 FF 07 FF 0F FF 00 00 00 00 00 00 00 00 00 00 00 00 00 00 00 00 00 00 00 00 00 00 00 00 00 00 00 00 00 00 00 00 00 00 00 00 00 00 03 FF
					39 01 00 00 00 00 30 B1 00 00 01 00 72 00 F0 01 A4 02 BC 03 A2 04 38 05 14 06 40 0F FF 0F FF 07 FF 0F FF 03 FF 07 FF 0F FF 0F FF 0F FF 0F FF 0F FF 0F FF 00 00 00 00
					39 01 00 00 00 00 65 B2 00 00 0E 10 0E 10 0E 10 0E 10 0E 10 0E 10 0E 10 0E 10 0E 10 0E 10 0E 10 0E 10 00 00 09 C4 09 C4 09 C4 09 C4 09 C4 09 C4 09 C4 09 C4 09 C4 09 C4 09 C4 09 C4 00 00 09 C4 09 C4 09 C4 09 C4 09 C4 09 C4 09 C4 09 C4 09 C4 09 C5 09 C4 09 C4 00 00 09 C4 09 C4 09 C4 09 C4 09 C4 09 C4 09 C4 09 C4 09 C4 09 C4
					39 01 00 00 00 00 27 B3 00 00 00 00 00 00 00 00 08 08 08 08 08 08 08 08 08 08 08 08 08 08 08 08 08 08 08 08 08 08 08 08 08 08 08 08 00 C0
					39 01 00 00 00 00 14 B4 01 02 07 01 5A 50 46 99 03 33 03 CC 02 33 00 66 00 99 00
					39 01 00 00 00 00 2E B5 0B 03 04 46 00 64 00 32 00 04 04 10 80 24 24 4C 2B 00 00 35 01 4C 00 00 00 00 00 24 24 00 00 00 00 06 00 00 00 24 02 00 55 55 00 00 00
					39 01 00 00 00 00 24 B6 00 01 01 23 45 67 01 23 45 67 05 04 03 02 01 00 00 00 00 00 00 00 00 00 00 00 00 00 00 00 00 00 00 00 00
					39 01 00 00 00 00 03 FF 3C 10
					39 01 00 00 00 00 09 B0 15 60 09 38 04 0e 01 00
					39 01 00 00 00 00 4C B1 00 00 00 00 00 00 00 03 01 00 00 03 41 17 00 00 01 17 09 00 00 00 00 00 00 00 00 00 00 00 00 00 03 01 00 00 03 41 17 00 00 01 17 09 00 00 00 00 00 00 00 00 00 00 00 00 09 17 01 00 00 17 41 03 00 00 01 03 00 00 00 00 00 00 00
					39 01 00 00 00 00 4C B2 00 00 00 00 00 00 09 17 01 00 00 17 41 03 00 00 01 03 00 00 00 00 00 00 00 00 00 00 00 00 00 00 03 01 00 00 03 41 17 00 00 01 17 09 00 00 00 00 00 00 00 00 00 00 00 00 00 03 01 00 00 03 41 17 00 00 01 17 09 00 00 00 00 00 00
					39 01 00 00 00 00 4C B3 00 00 00 00 00 00 09 17 01 00 00 17 41 03 00 00 01 03 00 00 00 00 00 00 00 00 00 00 00 00 00 00 03 01 00 00 03 41 17 00 00 01 17 09 00 00 00 00 00 00 00 00 00 00 00 00 00 03 01 00 00 03 41 17 00 00 01 17 09 00 00 00 00 00 00
					39 01 00 00 00 00 4C B4 00 00 00 00 00 00 00 03 01 00 00 03 41 17 00 00 01 17 09 00 00 00 00 00 00 00 00 00 00 00 00 00 03 01 00 00 03 41 17 00 00 01 17 09 00 00 00 00 00 00 00 00 00 00 00 00 09 17 01 00 00 17 41 03 00 00 01 03 00 00 00 00 00 00 00
					39 01 00 00 00 00 03 FF 3C 11
					39 01 00 00 00 00 4F B1 FF FF FF FF FF FF FF FF FF FB FF FF F9 FF FF F3 FF FC F0 FF FA EC FF F9 E7 FF F5 DA FF EF CB FF E9 B7 FF DE 9D FF CA 6F FF FF FF FF FF FF FF FF FF FF FF FF FF FF FF FF FF FF FF FF FF FF FF FF FF FF FF FF FF FF FF FF FF FF FF FF FF 00
					39 01 00 00 00 00 03 FF 3C 0B
					39 01 00 00 00 00 05 B3 01 01 00 B0
					39 01 00 00 05 00 02 70 02
					39 01 00 00 00 00 02 03 11
					39 01 00 00 00 00 05 2A 00 00 04 37
					39 01 00 00 00 00 05 2B 00 00 09 5F
					39 01 00 00 00 00 03 44 05 FF
					39 01 00 00 00 00 02 35 00
					39 01 00 00 00 00 03 4A FF 03
					39 01 00 00 00 00 03 4C FF 03
					39 01 00 00 00 00 03 51 FF 07
					39 01 00 00 00 00 02 53 21
					39 01 00 00 00 00 02 7B 01
					05 01 00 00 0A 00 02 11 00
					05 01 00 00 19 00 02 29 00
				];
				qcom,mdss-dsi-off-command = [
					05 01 00 00 34 00 02 10 00
					05 01 00 00 14 00 02 28 00
				];
				qcom,mdss-dsi-on-command-state = "dsi_lp_mode";
				qcom,mdss-dsi-off-command-state = "dsi_hs_mode";
				qcom,mdss-dsi-h-sync-pulse = <0>;
				qcom,compression-mode = "dsc";
				qcom,mdss-dsc-slice-height = <20>;
				qcom,mdss-dsc-slice-width = <540>;
				qcom,mdss-dsc-slice-per-pkt = <2>;
				qcom,mdss-dsc-bit-per-component = <8>;
				qcom,mdss-dsc-bit-per-pixel = <8>;
				qcom,mdss-dsc-block-prediction-enable;
			};
		};
	};
};
